AUTOSAR XML (schema 00048)
package /ComponentTypes
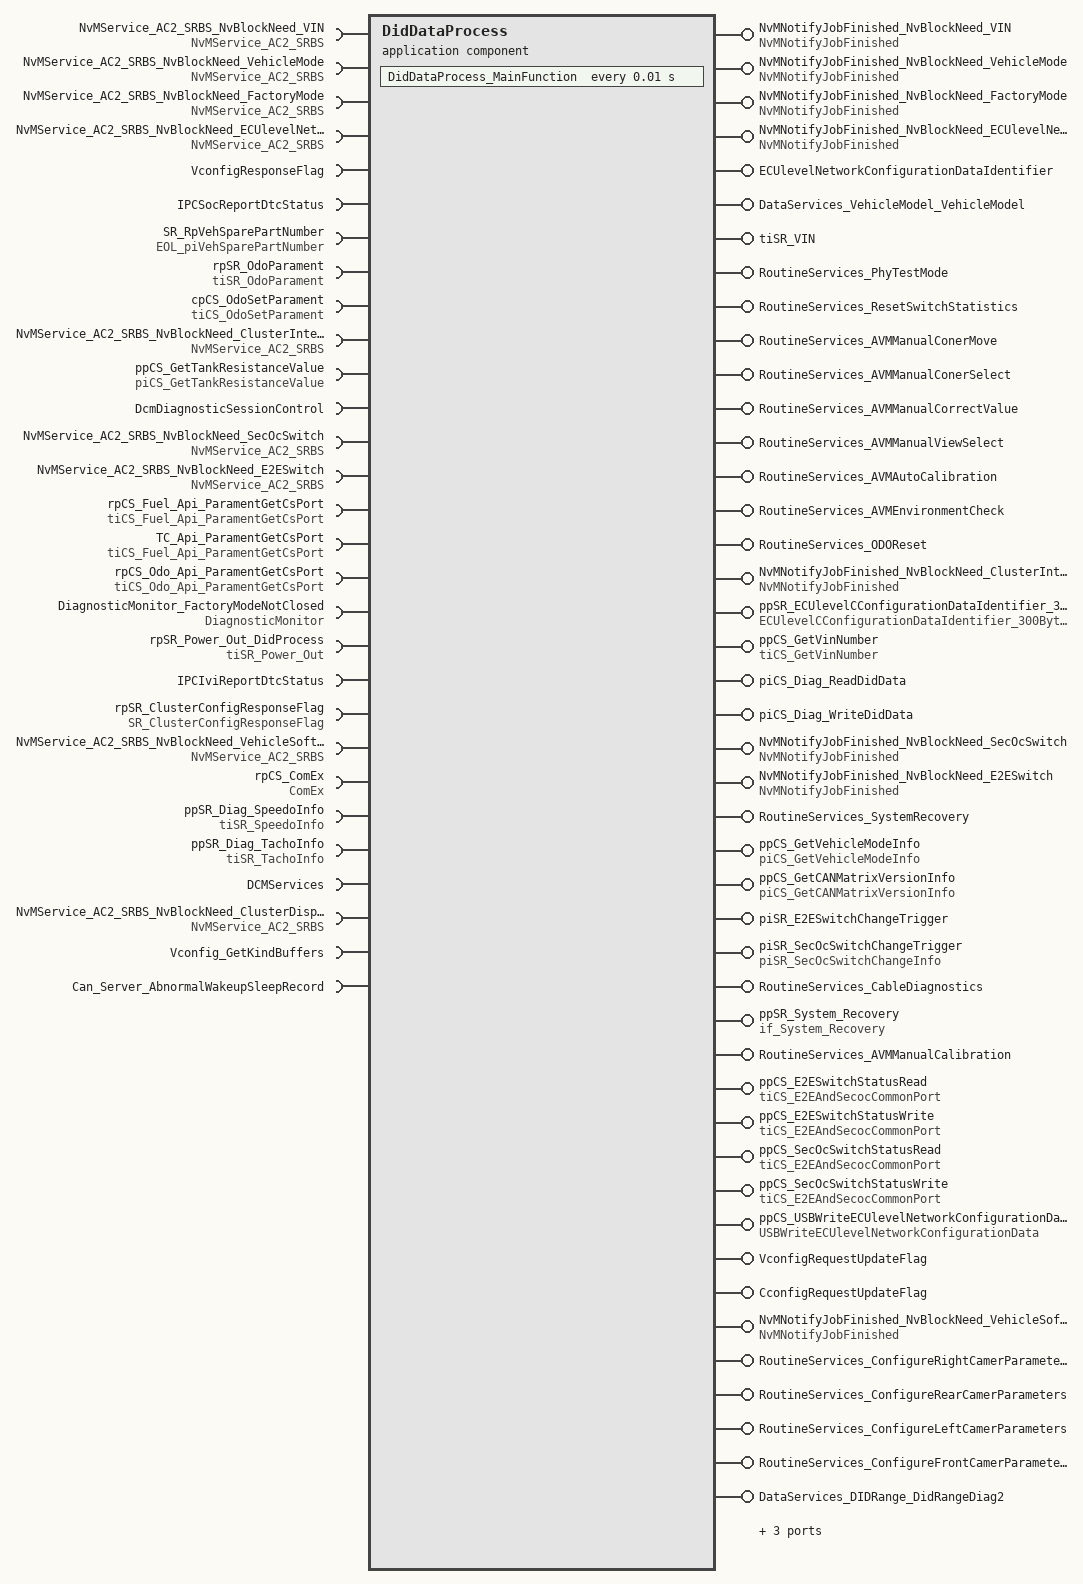
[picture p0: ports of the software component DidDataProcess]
  application sw component type DidDataProcess
    provide port NvMNotifyJobFinished_NvBlockNeed_VIN: server-com-spec{operation=JobFinished, queue-length=1}, provided-interface=NvMNotifyJobFinished
    require port NvMService_AC2_SRBS_NvBlockNeed_VIN: required-com-specs=[GetErrorStatus, ReadBlock, SetRamBlockStatus, WriteBlock], required-interface=NvMService_AC2_SRBS
    provide port NvMNotifyJobFinished_NvBlockNeed_VehicleMode: server-com-spec{operation=JobFinished, queue-length=1}, provided-interface=NvMNotifyJobFinished
    require port NvMService_AC2_SRBS_NvBlockNeed_VehicleMode: required-com-specs=[GetErrorStatus, ReadBlock, SetRamBlockStatus, WriteBlock], required-interface=NvMService_AC2_SRBS
    provide port NvMNotifyJobFinished_NvBlockNeed_FactoryMode: server-com-spec{operation=JobFinished, queue-length=1}, provided-interface=NvMNotifyJobFinished
    require port NvMService_AC2_SRBS_NvBlockNeed_FactoryMode: required-com-specs=[GetErrorStatus, ReadBlock, SetRamBlockStatus, WriteBlock], required-interface=NvMService_AC2_SRBS
    provide port NvMNotifyJobFinished_NvBlockNeed_ECUlevelNetworkConfigurationData: server-com-spec{operation=JobFinished, queue-length=1}, provided-interface=NvMNotifyJobFinished
    require port NvMService_AC2_SRBS_NvBlockNeed_ECUlevelNetworkConfigurationData: required-com-specs=[GetErrorStatus, ReadBlock, SetRamBlockStatus, WriteBlock], required-interface=NvMService_AC2_SRBS
    provide port ECUlevelNetworkConfigurationDataIdentifier: nonqueued-sender-com-spec{data-element=Element, init-value=200 x 0}, provided-interface=ECUlevelNetworkConfigurationDataIdentifier
    require port VconfigResponseFlag: nonqueued-receiver-com-spec{data-element=VconfigResponseFlag, filter=data-filter-type=ALWAYS, init-value=0}, required-interface=VconfigResponseFlag
    require port IPCSocReportDtcStatus: client-com-spec=IpcSocReportDtcStatus, required-interface=IPCSocReportDtcStatus
    11 x provide port:
      DataServices_VehicleModel_VehicleModel: provided-interface=DataServices_VehicleModel_VehicleModel
        provided-com-specs:
          operation=WriteData, queue-length=1
          operation=ConditionCheckRead, queue-length=1
          operation=ReadData, queue-length=1
      tiSR_VIN: nonqueued-sender-com-spec{data-element=Element, init-value=17 x 0}, provided-interface=tiSR_VIN
      RoutineServices_PhyTestMode: server-com-spec{operation=Start, queue-length=1}, provided-interface=RoutineServices_PhyTestMode
      RoutineServices_ResetSwitchStatistics: server-com-spec{operation=Start, queue-length=1}, provided-interface=RoutineServices_ResetSwitchStatistics
      RoutineServices_AVMManualConerMove: provided-com-specs=[{operation=RequestResults, queue-length=1}, {operation=Start, queue-length=1}], provided-interface=RoutineServices_AVMManualConerMove
      RoutineServices_AVMManualConerSelect: provided-com-specs=[{operation=RequestResults, queue-length=1}, {operation=Start, queue-length=1}], provided-interface=RoutineServices_AVMManualConerSelect
      RoutineServices_AVMManualCorrectValue: provided-com-specs=[{operation=RequestResults, queue-length=1}, {operation=Start, queue-length=1}], provided-interface=RoutineServices_AVMManualCorrectValue
      RoutineServices_AVMManualViewSelect: provided-com-specs=[{operation=RequestResults, queue-length=1}, {operation=Start, queue-length=1}], provided-interface=RoutineServices_AVMManualViewSelect
      RoutineServices_AVMAutoCalibration: provided-com-specs=[{operation=RequestResults, queue-length=1}, {operation=Start, queue-length=1}], provided-interface=RoutineServices_AVMAutoCalibration
      RoutineServices_AVMEnvironmentCheck: provided-com-specs=[{operation=RequestResults, queue-length=1}, {operation=Start, queue-length=1}], provided-interface=RoutineServices_AVMEnvironmentCheck
      RoutineServices_ODOReset: provided-com-specs=[{operation=Start, queue-length=1}, {operation=RequestResults, queue-length=1}], provided-interface=RoutineServices_ODOReset
    require port SR_RpVehSparePartNumber: nonqueued-receiver-com-spec{data-element=SparePartNumber, filter=data-filter-type=ALWAYS, init-value=13 x 0}, required-interface=EOL_piVehSparePartNumber
    require port rpSR_OdoParament: nonqueued-receiver-com-spec{data-element=Element, filter=data-filter-type=ALWAYS, init-value=constant-reference=SocRpOdoDataInit}, required-interface=tiSR_OdoParament
    require port cpCS_OdoSetParament: client-com-spec=Operation, required-interface=tiCS_OdoSetParament
    provide port NvMNotifyJobFinished_NvBlockNeed_ClusterInternalConfiguration: server-com-spec{operation=JobFinished, queue-length=1}, provided-interface=NvMNotifyJobFinished
    require port NvMService_AC2_SRBS_NvBlockNeed_ClusterInternalConfiguration: required-com-specs=[WriteBlock, SetRamBlockStatus, ReadBlock, GetErrorStatus], required-interface=NvMService_AC2_SRBS
    require port ppCS_GetTankResistanceValue: client-com-spec=Operation, required-interface=piCS_GetTankResistanceValue
    require port DcmDiagnosticSessionControl: mode-switch-receiver-com-spec=DcmDiagnosticSessionControl, required-interface=DcmDiagnosticSessionControl
    5 x provide port:
      ppSR_ECUlevelCConfigurationDataIdentifier_300Bytes: nonqueued-sender-com-spec=Element, provided-interface=ECUlevelCConfigurationDataIdentifier_300Bytes
      ppCS_GetVinNumber: server-com-spec{operation=Operation, queue-length=1}, provided-interface=tiCS_GetVinNumber
      piCS_Diag_ReadDidData: server-com-spec{operation=Operation, queue-length=1}, provided-interface=piCS_Diag_ReadDidData
      piCS_Diag_WriteDidData: server-com-spec{operation=Operation, queue-length=1}, provided-interface=piCS_Diag_WriteDidData
      NvMNotifyJobFinished_NvBlockNeed_SecOcSwitch: server-com-spec{operation=JobFinished, queue-length=1}, provided-interface=NvMNotifyJobFinished
    require port NvMService_AC2_SRBS_NvBlockNeed_SecOcSwitch: required-com-specs=[WriteBlock, SetRamBlockStatus, ReadBlock, GetErrorStatus], required-interface=NvMService_AC2_SRBS
    provide port NvMNotifyJobFinished_NvBlockNeed_E2ESwitch: server-com-spec{operation=JobFinished, queue-length=1}, provided-interface=NvMNotifyJobFinished
    require port NvMService_AC2_SRBS_NvBlockNeed_E2ESwitch: required-com-specs=[WriteBlock, SetRamBlockStatus, ReadBlock, GetErrorStatus], required-interface=NvMService_AC2_SRBS
    provide port RoutineServices_SystemRecovery: server-com-spec{operation=Start, queue-length=1}, provided-interface=RoutineServices_SystemRecovery
    require port rpCS_Fuel_Api_ParamentGetCsPort: client-com-spec=Operation, required-interface=tiCS_Fuel_Api_ParamentGetCsPort
    require port TC_Api_ParamentGetCsPort: client-com-spec=Operation, required-interface=tiCS_Fuel_Api_ParamentGetCsPort
    provide port ppCS_GetVehicleModeInfo: server-com-spec{operation=Data, queue-length=1}, provided-interface=piCS_GetVehicleModeInfo
    provide port ppCS_GetCANMatrixVersionInfo: server-com-spec{operation=Data, queue-length=1}, provided-interface=piCS_GetCANMatrixVersionInfo
    require port rpCS_Odo_Api_ParamentGetCsPort: client-com-spec=Operation, required-interface=tiCS_Odo_Api_ParamentGetCsPort
    4 x provide port:
      piSR_E2ESwitchChangeTrigger: nonqueued-sender-com-spec{data-element=Element, init-value=0}, provided-interface=piSR_E2ESwitchChangeTrigger
      piSR_SecOcSwitchChangeTrigger: nonqueued-sender-com-spec=Element, provided-interface=piSR_SecOcSwitchChangeInfo
      RoutineServices_CableDiagnostics: server-com-spec{operation=Start, queue-length=1}, provided-interface=RoutineServices_CableDiagnostics
      ppSR_System_Recovery: nonqueued-sender-com-spec{data-element=System_Recovery, init-value=0}, provided-interface=if_System_Recovery
    require port DiagnosticMonitor_FactoryModeNotClosed: required-interface=DiagnosticMonitor
      required-com-specs:
        GetEventExtendedDataRecordEx
        GetEventFreezeFrameDataEx
        GetFaultDetectionCounter
        GetDTCOfEvent
        GetEventTested
        GetEventFailed
        GetEventStatus
        GetEventUdsStatus
        ResetEventDebounceStatus
        ResetEventStatus
        SetEventStatus
    provide port RoutineServices_AVMManualCalibration: provided-interface=RoutineServices_AVMManualCalibration
      provided-com-specs:
        operation=Stop, queue-length=1
        operation=RequestResults, queue-length=1
        operation=Start, queue-length=1
    require port rpSR_Power_Out_DidProcess: nonqueued-receiver-com-spec{data-element=SystemStateOut, filter=data-filter-type=ALWAYS, init-value=fields=[ClusterState:0, IVIState:0, HUDState:0, ConsoleState:0, KL15State:0, {short-label=s_PowerVoltage, fields=[state:0, value:0]}, SP_State:0, {short-label=s_TempVoltage, fields=[state:0, temperature:0]}]}, required-interface=tiSR_Power_Out
    4 x provide port, all with server-com-spec{operation=Operation, queue-length=1}, provided-interface=tiCS_E2EAndSecocCommonPort:
      ppCS_E2ESwitchStatusRead
      ppCS_E2ESwitchStatusWrite
      ppCS_SecOcSwitchStatusRead
      ppCS_SecOcSwitchStatusWrite
    require port IPCIviReportDtcStatus: client-com-spec=IpcIviReportDtcSts, required-interface=IPCIviReportDtcStatus
    require port rpSR_ClusterConfigResponseFlag: nonqueued-receiver-com-spec{data-element=ClusterConfigResponseFlag, filter=data-filter-type=ALWAYS, init-value=0}, required-interface=SR_ClusterConfigResponseFlag
    provide port ppCS_USBWriteECUlevelNetworkConfigurationData: server-com-spec{operation=USBWriteData, queue-length=1}, provided-interface=USBWriteECUlevelNetworkConfigurationData
    provide port VconfigRequestUpdateFlag: nonqueued-sender-com-spec{data-element=VconfigRequestUpdateFlag, init-value=0}, provided-interface=VconfigRequestUpdateFlag
    provide port CconfigRequestUpdateFlag: nonqueued-sender-com-spec{data-element=CconfigRequestUpdateFlag, init-value=0}, provided-interface=CconfigRequestUpdateFlag
    require port NvMService_AC2_SRBS_NvBlockNeed_VehicleSoftwareVersion: required-com-specs=[WriteBlock, SetRamBlockStatus, ReadBlock, GetErrorStatus], required-interface=NvMService_AC2_SRBS
    provide port NvMNotifyJobFinished_NvBlockNeed_VehicleSoftwareVersion: server-com-spec{operation=JobFinished, queue-length=1}, provided-interface=NvMNotifyJobFinished
    require port rpCS_ComEx: required-com-specs=[SendSignal, ReceiveSignal, GetRxE2EStatus], required-interface=ComEx
    4 x provide port, all with provided-com-specs=[{operation=RequestResults, queue-length=1}, {operation=Start, queue-length=1}]:
      RoutineServices_ConfigureRightCamerParameters: provided-interface=RoutineServices_ConfigureRightCamerParameters
      RoutineServices_ConfigureRearCamerParameters: provided-interface=RoutineServices_ConfigureRearCamerParameters
      RoutineServices_ConfigureLeftCamerParameters: provided-interface=RoutineServices_ConfigureLeftCamerParameters
      RoutineServices_ConfigureFrontCamerParameters: provided-interface=RoutineServices_ConfigureFrontCamerParameters
    require port ppSR_Diag_SpeedoInfo: nonqueued-receiver-com-spec{data-element=Element, filter=data-filter-type=ALWAYS, init-value=fields=[OverSpdWrnFlg:0, VehRunSts:0, IndicateSpeed:0, RealSpeed:0, IndicateSpeedMile:0, RealSpeedMile:0, RealSpeedBak:0, Msg_missingSts:0, VehSpdVld:0]}, required-interface=tiSR_SpeedoInfo
    require port ppSR_Diag_TachoInfo: nonqueued-receiver-com-spec{data-element=Element, filter=data-filter-type=ALWAYS, init-value=fields=[EngRunSts:0, EngSpd:0, TimeOutFlag:0, EngSpdBak:0, Msg_missingSts:0]}, required-interface=tiSR_TachoInfo
    require port DCMServices: required-interface=DCMServices
      required-com-specs:
        GetRequestKind
        SetActiveDiagnostic
        GetSecurityLevel
        ResetToDefaultSession
        GetSesCtrlType
        GetActiveProtocol
    provide port DataServices_DIDRange_DidRangeDiag2: provided-interface=DataServices_DIDRange_DidRangeDiag2
      provided-com-specs:
        operation=IsDidAvailable, queue-length=1
        operation=WriteDidData, queue-length=1
        operation=ReadDidData, queue-length=1
    provide port DataServices_DIDRange_DidRangeDiag1: provided-interface=DataServices_DIDRange_DidRangeDiag1
      provided-com-specs:
        operation=IsDidAvailable, queue-length=1
        operation=WriteDidData, queue-length=1
        operation=ReadDidData, queue-length=1
    provide port NvMNotifyJobFinished_NvBlockNeed_ClusterDisplayHMIAdjustmentOffset: server-com-spec{operation=JobFinished, queue-length=1}, provided-interface=NvMNotifyJobFinished
    require port NvMService_AC2_SRBS_NvBlockNeed_ClusterDisplayHMIAdjustmentOffset: required-com-specs=[WriteBlock, SetRamBlockStatus, ReadBlock, GetErrorStatus], required-interface=NvMService_AC2_SRBS
    require port Vconfig_GetKindBuffers: nonqueued-receiver-com-spec{data-element=AllKinds, filter=data-filter-type=ALWAYS, init-value=600 x 0}, required-interface=Vconfig_GetKindBuffers
    provide port RoutineServices_RequestCertificateStatus: provided-com-specs=[{operation=RequestResults, queue-length=1}, {operation=Start, queue-length=1}], provided-interface=RoutineServices_RequestCertificateStatus
    require port Can_Server_AbnormalWakeupSleepRecord: client-com-spec=Get, required-interface=Can_Server_AbnormalWakeupSleepRecord
    behavior DidDataProcess_InternalBehavior
      ar-typed-per-instance-memorys:
        10 x data, all with sw-calibration-access=READ-ONLY:
          NvBlockNeed_VIN_MirrorBlock: type=A_17Bytes
          NvBlockNeed_VehicleMode_MirrorBlock: type=Dcm_Data20ByteType
          NvBlockNeed_FactoryMode_MirrorBlock: type=A_1Bytes
          NvBlockNeed_ECUlevelNetworkConfigurationData_MirrorBlock: type=A_200Bytes
          NvBlockNeed_HUTInternalConfiguration_MirrorBlock: type=Dcm_Data4ByteType
          NvBlockNeed_ClusterInternalConfiguration_MirrorBlock: type=A_300Bytes
          NvBlockNeed_SecOcSwitch_MirrorBlock: type=A_1Bytes
          NvBlockNeed_E2ESwitch_MirrorBlock: type=A_1Bytes
          NvBlockNeed_VehicleSoftwareVersion_MirrorBlock: type=A_30Bytes
          NvBlockNeed_ClusterDisplayHMIAdjustmentOffset_MirrorBlock: type=A_8Bytes
      init event DidDataProcess_InitEvent: start-on-event=DidDataProcess_Init
      timing event TMT_DidDataProcess_MainFunction: start-on-event=DidDataProcess_MainFunction, period=0.01
      59 x operation invoked event:
        OIT_NvMNotifyJobFinished_NvBlockNeed_VIN_JobFinished_NvMNotifyJobFinished_NvBlockNeed_VIN_JobFinished: start-on-event=NvMNotifyJobFinished_NvBlockNeed_VIN_JobFinished, operation=NvMNotifyJobFinished_NvBlockNeed_VIN.JobFinished
        OIT_NvMNotifyJobFinished_NvBlockNeed_VehicleMode_JobFinished_NvMNotifyJobFinished_NvBlockNeed_VehicleMode_JobFinished: start-on-event=NvMNotifyJobFinished_NvBlockNeed_VehicleMode_JobFinished, operation=NvMNotifyJobFinished_NvBlockNeed_VehicleMode.JobFinished
        OIT_NvMNotifyJobFinished_NvBlockNeed_FactoryMode_JobFinished_NvMNotifyJobFinished_NvBlockNeed_FactoryMode_JobFinished: start-on-event=NvMNotifyJobFinished_NvBlockNeed_FactoryMode_JobFinished, operation=NvMNotifyJobFinished_NvBlockNeed_FactoryMode.JobFinished
        OIT_NvMNotifyJobFinished_NvBlockNeed_ECUlevelNetworkConfigurationData_JobFinished_NvMNotifyJobFinished_NvBlockNeed_ECUleB6E309F8: start-on-event=NvMNotifyJobFinished_NvBlockNeed_ECUlevelNetworkConfigurationData_JobFinished, operation=NvMNotifyJobFinished_NvBlockNeed_ECUlevelNetworkConfigurationData.JobFinished
        OIT_DataServices_VehicleModel_VehicleModel_WriteData_DataServices_VehicleModel_VehicleModel_WriteData: start-on-event=DataServices_VehicleModel_VehicleModel_WriteData, operation=DataServices_VehicleModel_VehicleModel.WriteData
        OIT_DataServices_VehicleModel_VehicleModel_ConditionCheckRead_DataServices_VehicleModel_VehicleModel_ConditionCheckRead: start-on-event=DataServices_VehicleModel_VehicleModel_ConditionCheckRead, operation=DataServices_VehicleModel_VehicleModel.ConditionCheckRead
        OIT_DataServices_VehicleModel_VehicleModel_ReadData_DataServices_VehicleModel_VehicleModel_ReadData: start-on-event=DataServices_VehicleModel_VehicleModel_ReadData, operation=DataServices_VehicleModel_VehicleModel.ReadData
        OIT_RoutineServices_ResetSwitchStatistics_Start_RoutineServices_ResetSwitchStatistics_Start: start-on-event=RoutineServices_ResetSwitchStatistics_Start, operation=RoutineServices_ResetSwitchStatistics.Start
        OIT_RoutineServices_PhyTestMode_Start_RoutineServices_PhyTestMode_Start: start-on-event=RoutineServices_PhyTestMode_Start, operation=RoutineServices_PhyTestMode.Start
        OIT_RoutineServices_AVMEnvironmentCheck_RequestResults_RoutineServices_AVMEnvironmentCheck_RequestResults: start-on-event=RoutineServices_AVMEnvironmentCheck_RequestResults, operation=RoutineServices_AVMEnvironmentCheck.RequestResults
        OIT_RoutineServices_AVMEnvironmentCheck_Start_RoutineServices_AVMEnvironmentCheck_Start: start-on-event=RoutineServices_AVMEnvironmentCheck_Start, operation=RoutineServices_AVMEnvironmentCheck.Start
        OIT_RoutineServices_AVMManualConerMove_RequestResults_RoutineServices_AVMManualConerMove_RequestResults: start-on-event=RoutineServices_AVMManualConerMove_RequestResults, operation=RoutineServices_AVMManualConerMove.RequestResults
        OIT_RoutineServices_AVMManualConerMove_Start_RoutineServices_AVMManualConerMove_Start: start-on-event=RoutineServices_AVMManualConerMove_Start, operation=RoutineServices_AVMManualConerMove.Start
        OIT_RoutineServices_AVMManualConerSelect_RequestResults_RoutineServices_AVMManualConerSelect_RequestResults: start-on-event=RoutineServices_AVMManualConerSelect_RequestResults, operation=RoutineServices_AVMManualConerSelect.RequestResults
        OIT_RoutineServices_AVMManualConerSelect_Start_RoutineServices_AVMManualConerSelect_Start: start-on-event=RoutineServices_AVMManualConerSelect_Start, operation=RoutineServices_AVMManualConerSelect.Start
        OIT_RoutineServices_AVMManualCorrectValue_RequestResults_RoutineServices_AVMManualCorrectValue_RequestResults: start-on-event=RoutineServices_AVMManualCorrectValue_RequestResults, operation=RoutineServices_AVMManualCorrectValue.RequestResults
        OIT_RoutineServices_AVMManualCorrectValue_Start_RoutineServices_AVMManualCorrectValue_Start: start-on-event=RoutineServices_AVMManualCorrectValue_Start, operation=RoutineServices_AVMManualCorrectValue.Start
        OIT_RoutineServices_AVMManualViewSelect_RequestResults_RoutineServices_AVMManualViewSelect_RequestResults: start-on-event=RoutineServices_AVMManualViewSelect_RequestResults, operation=RoutineServices_AVMManualViewSelect.RequestResults
        OIT_RoutineServices_AVMManualViewSelect_Start_RoutineServices_AVMManualViewSelect_Start: start-on-event=RoutineServices_AVMManualViewSelect_Start, operation=RoutineServices_AVMManualViewSelect.Start
        OIT_RoutineServices_AVMAutoCalibration_RequestResults_RoutineServices_AVMAutoCalibration_RequestResults: start-on-event=RoutineServices_AVMAutoCalibration_RequestResults, operation=RoutineServices_AVMAutoCalibration.RequestResults
        OIT_RoutineServices_AVMAutoCalibration_Start_RoutineServices_AVMAutoCalibration_Start: start-on-event=RoutineServices_AVMAutoCalibration_Start, operation=RoutineServices_AVMAutoCalibration.Start
        OIT_NvMNotifyJobFinished_NvBlockNeed_ClusterInternalConfiguration_JobFinished_NvMNotifyJobFinished_NvBlockNeed_ClusterIn67862731: start-on-event=NvMNotifyJobFinished_NvBlockNeed_ClusterInternalConfiguration_JobFinished, operation=NvMNotifyJobFinished_NvBlockNeed_ClusterInternalConfiguration.JobFinished
        OIT_AppGetVinNumberFunction_ppCS_GetVinNumber_Operation: start-on-event=AppGetVinNumberFunction, operation=ppCS_GetVinNumber.Operation
        OIT_piCS_Diag_WriteDidData_Operation_piCS_Diag_WriteDidData_Operation: start-on-event=ppCS_Diag_WriteDidData_Operation, operation=piCS_Diag_WriteDidData.Operation
        OIT_piCS_Diag_ReadDidData_Operation_piCS_Diag_ReadDidData_Operation: start-on-event=ppCS_Diag_ReadDidData_Operation, operation=piCS_Diag_ReadDidData.Operation
        OIT_NvMNotifyJobFinished_NvBlockNeed_E2ESwitch_JobFinished_NvMNotifyJobFinished_NvBlockNeed_E2ESwitch_JobFinished: start-on-event=NvMNotifyJobFinished_NvBlockNeed_E2ESwitch_JobFinished, operation=NvMNotifyJobFinished_NvBlockNeed_E2ESwitch.JobFinished
        OIT_NvMNotifyJobFinished_NvBlockNeed_SecOcSwitch_JobFinished_NvMNotifyJobFinished_NvBlockNeed_SecOcSwitch_JobFinished: start-on-event=NvMNotifyJobFinished_NvBlockNeed_SecOcSwitch_JobFinished, operation=NvMNotifyJobFinished_NvBlockNeed_SecOcSwitch.JobFinished
        OIT_RoutineServices_SystemRecovery_Start_RoutineServices_SystemRecovery_Start: start-on-event=RoutineServices_SystemRecovery_Start, operation=RoutineServices_SystemRecovery.Start
        OIT_ppCS_GetCANMatrixVersionInfo_Data_ppCS_GetCANMatrixVersionInfo_Data: start-on-event=GetCANMatrixVersionInfo_Data, operation=ppCS_GetCANMatrixVersionInfo.Data
        OIT_ppCS_GetVehicleModeInfo_Data_ppCS_GetVehicleModeInfo_Data: start-on-event=GetVehicleModeInfo_Data, operation=ppCS_GetVehicleModeInfo.Data
        OIT_RoutineServices_ODOReset_RequestResults_RoutineServices_ODOReset_RequestResults: start-on-event=RoutineServices_ODOReset_RequestResults, operation=RoutineServices_ODOReset.RequestResults
        OIT_RoutineServices_ODOReset_Start_RoutineServices_ODOReset_Start: start-on-event=RoutineServices_ODOReset_Start, operation=RoutineServices_ODOReset.Start
        OIT_RoutineServices_CableDiagnostics_Start_RoutineServices_CableDiagnostics_Start: start-on-event=RoutineServices_CableDiagnostics_Start, operation=RoutineServices_CableDiagnostics.Start
        OIT_RoutineServices_AVMManualCalibration_Stop_RoutineServices_AVMManualCalibration_Stop: start-on-event=RoutineServices_AVMManualCalibration_Stop, operation=RoutineServices_AVMManualCalibration.Stop
        OIT_RoutineServices_AVMManualCalibration_RequestResults_RoutineServices_AVMManualCalibration_RequestResults: start-on-event=RoutineServices_AVMManualCalibration_RequestResults, operation=RoutineServices_AVMManualCalibration.RequestResults
        OIT_RoutineServices_AVMManualCalibration_Start_RoutineServices_AVMManualCalibration_Start: start-on-event=RoutineServices_AVMManualCalibration_Start, operation=RoutineServices_AVMManualCalibration.Start
        OIT_ppCS_SecOcSwitchStatusRead_Operation_ppCS_SecOcSwitchStatusRead_Operation: start-on-event=SecOcSwitchStatusRead, operation=ppCS_SecOcSwitchStatusRead.Operation
        OIT_ppCS_SecOcSwitchStatusWrite_Operation_ppCS_SecOcSwitchStatusWrite_Operation: start-on-event=SecOcSwitchStatusWrite, operation=ppCS_SecOcSwitchStatusWrite.Operation
        OIT_ppCS_E2ESwitchStatusRead_Operation_ppCS_E2ESwitchStatusRead_Operation: start-on-event=E2ESwitchStatusRead, operation=ppCS_E2ESwitchStatusRead.Operation
        OIT_ppCS_E2ESwitchStatusWrite_Operation_ppCS_E2ESwitchStatusWrite_Operation: start-on-event=E2ESwitchStatusWrite, operation=ppCS_E2ESwitchStatusWrite.Operation
        OIT_ppCS_USBWriteECUlevelNetworkConfigurationData_USBWriteData_ppCS_USBWriteECUlevelNetworkConfigurationData_USBWriteData: start-on-event=ppCS_USBWriteECUlevelNetworkConfigurationData_USBWriteData, operation=ppCS_USBWriteECUlevelNetworkConfigurationData.USBWriteData
        OIT_NvMNotifyJobFinished_NvBlockNeed_VehicleSoftwareVersion_JobFinished_NvMNotifyJobFinished_NvBlockNeed_VehicleSoftware10887BBF: start-on-event=NvMNotifyJobFinished_NvBlockNeed_VehicleSoftwareVersion_JobFinished, operation=NvMNotifyJobFinished_NvBlockNeed_VehicleSoftwareVersion.JobFinished
        OIT_RoutineServices_ConfigureRightCamerParameters_RequestResults_RoutineServices_ConfigureRightCamerParameters_RequestResults: start-on-event=RoutineServices_ConfigureRightCamerParameters_RequestResults, operation=RoutineServices_ConfigureRightCamerParameters.RequestResults
        OIT_RoutineServices_ConfigureRightCamerParameters_Start_RoutineServices_ConfigureRightCamerParameters_Start: start-on-event=RoutineServices_ConfigureRightCamerParameters_Start, operation=RoutineServices_ConfigureRightCamerParameters.Start
        OIT_RoutineServices_ConfigureRearCamerParameters_RequestResults_RoutineServices_ConfigureRearCamerParameters_RequestResults: start-on-event=RoutineServices_ConfigureRearCamerParameters_RequestResults, operation=RoutineServices_ConfigureRearCamerParameters.RequestResults
        OIT_RoutineServices_ConfigureRearCamerParameters_Start_RoutineServices_ConfigureRearCamerParameters_Start: start-on-event=RoutineServices_ConfigureRearCamerParameters_Start, operation=RoutineServices_ConfigureRearCamerParameters.Start
        OIT_RoutineServices_ConfigureLeftCamerParameters_RequestResults_RoutineServices_ConfigureLeftCamerParameters_RequestResults: start-on-event=RoutineServices_ConfigureLeftCamerParameters_RequestResults, operation=RoutineServices_ConfigureLeftCamerParameters.RequestResults
        OIT_RoutineServices_ConfigureLeftCamerParameters_Start_RoutineServices_ConfigureLeftCamerParameters_Start: start-on-event=RoutineServices_ConfigureLeftCamerParameters_Start, operation=RoutineServices_ConfigureLeftCamerParameters.Start
        OIT_RoutineServices_ConfigureFrontCamerParameters_RequestResults_RoutineServices_ConfigureFrontCamerParameters_RequestResults: start-on-event=RoutineServices_ConfigureFrontCamerParameters_RequestResults, operation=RoutineServices_ConfigureFrontCamerParameters.RequestResults
        OIT_RoutineServices_ConfigureFrontCamerParameters_Start_RoutineServices_ConfigureFrontCamerParameters_Start: start-on-event=RoutineServices_ConfigureFrontCamerParameters_Start, operation=RoutineServices_ConfigureFrontCamerParameters.Start
        OIT_DataServices_DIDRange_DidRangeDiag2_IsDidAvailable_DataServices_DIDRange_DidRangeDiag2_IsDidAvailable: start-on-event=DataServices_DIDRange_DidRangeDiag2_IsDidAvailable, operation=DataServices_DIDRange_DidRangeDiag2.IsDidAvailable
        OIT_DataServices_DIDRange_DidRangeDiag2_WriteDidData_DataServices_DIDRange_DidRangeDiag2_WriteDidData: start-on-event=DataServices_DIDRange_DidRangeDiag2_WriteDidData, operation=DataServices_DIDRange_DidRangeDiag2.WriteDidData
        OIT_DataServices_DIDRange_DidRangeDiag2_ReadDidData_DataServices_DIDRange_DidRangeDiag2_ReadDidData: start-on-event=DataServices_DIDRange_DidRangeDiag2_ReadDidData, operation=DataServices_DIDRange_DidRangeDiag2.ReadDidData
        OIT_DataServices_DIDRange_DidRangeDiag1_IsDidAvailable_DataServices_DIDRange_DidRangeDiag1_IsDidAvailable: start-on-event=DataServices_DIDRange_DidRangeDiag1_IsDidAvailable, operation=DataServices_DIDRange_DidRangeDiag1.IsDidAvailable
        OIT_DataServices_DIDRange_DidRangeDiag1_WriteDidData_DataServices_DIDRange_DidRangeDiag1_WriteDidData: start-on-event=DataServices_DIDRange_DidRangeDiag1_WriteDidData, operation=DataServices_DIDRange_DidRangeDiag1.WriteDidData
        OIT_DataServices_DIDRange_DidRangeDiag1_ReadDidData_DataServices_DIDRange_DidRangeDiag1_ReadDidData: start-on-event=DataServices_DIDRange_DidRangeDiag1_ReadDidData, operation=DataServices_DIDRange_DidRangeDiag1.ReadDidData
        OIT_NvMNotifyJobFinished_NvBlockNeed_ClusterDisplayHMIAdjustmentOffset_JobFinished_NvMNotifyJobFinished_NvBlockNeed_Clus23676530: start-on-event=NvMNotifyJobFinished_NvBlockNeed_ClusterDisplayHMIAdjustmentOffset_JobFinished, operation=NvMNotifyJobFinished_NvBlockNeed_ClusterDisplayHMIAdjustmentOffset.JobFinished
        OIT_RoutineServices_RequestCertificateStatus_RequestResults_RoutineServices_RequestCertificateStatus_RequestResults: start-on-event=RoutineServices_RequestCertificateStatus_RequestResults, operation=RoutineServices_RequestCertificateStatus.RequestResults
        OIT_RoutineServices_RequestCertificateStatus_Start_RoutineServices_RequestCertificateStatus_Start: start-on-event=RoutineServices_RequestCertificateStatus_Start, operation=RoutineServices_RequestCertificateStatus.Start
      port-api-options:
        enable-take-address=false, error-handling=NO-TRANSFORMER-ERROR-HANDLING, indirect-api=false, port=cpCS_OdoSetParament
        enable-take-address=true, error-handling=NO-TRANSFORMER-ERROR-HANDLING, indirect-api=false, port=piCS_Diag_WriteDidData
        enable-take-address=true, error-handling=NO-TRANSFORMER-ERROR-HANDLING, indirect-api=false, port=piCS_Diag_ReadDidData
        enable-take-address=true, error-handling=NO-TRANSFORMER-ERROR-HANDLING, indirect-api=false, port=ppCS_GetVehicleModeInfo
        enable-take-address=true, error-handling=NO-TRANSFORMER-ERROR-HANDLING, indirect-api=false, port=ppCS_GetCANMatrixVersionInfo
      61 x runnable:
        DidDataProcess_Init
        DidDataProcess_MainFunction: mode-access-point=DcmDiagnosticSessionControl.DcmDiagnosticSessionControl
          data-receive-point-by-arguments:
            8 x access:
              REC_SR_RpVehSparePartNumber_SparePartNumber: accessed-variable=SR_RpVehSparePartNumber.SparePartNumber
              REC_ppSR_Diag_SpeedoInfo_Element: accessed-variable=ppSR_Diag_SpeedoInfo.Element
              REC_ppSR_Diag_TachoInfo_Element: accessed-variable=ppSR_Diag_TachoInfo.Element
              REC_VconfigResponseFlag_VconfigResponseFlag: accessed-variable=VconfigResponseFlag.VconfigResponseFlag
              REC_rpSR_ClusterConfigResponseFlag_ClusterConfigResponseFlag: accessed-variable=rpSR_ClusterConfigResponseFlag.ClusterConfigResponseFlag
              REC_rpSR_OdoParament_Element: accessed-variable=rpSR_OdoParament.Element
              REC_rpSR_Power_Out_DidProcess_SystemStateOut: accessed-variable=rpSR_Power_Out_DidProcess.SystemStateOut
              REC_Vconfig_GetKindBuffers_Kind600Bytes: accessed-variable=Vconfig_GetKindBuffers.AllKinds
          data-send-points:
            8 x access:
              SEND_tiSR_VIN_Element: accessed-variable=tiSR_VIN.Element
              SEND_CconfigRequestUpdateFlag_CconfigRequestUpdateFlag: accessed-variable=CconfigRequestUpdateFlag.CconfigRequestUpdateFlag
              SEND_ECUlevelNetworkConfigurationDataIdentifier_Element: accessed-variable=ECUlevelNetworkConfigurationDataIdentifier.Element
              SEND_VconfigRequestUpdateFlag_VconfigRequestUpdateFlag: accessed-variable=VconfigRequestUpdateFlag.VconfigRequestUpdateFlag
              SEND_piSR_E2ESwitchChangeTrigger_Element: accessed-variable=piSR_E2ESwitchChangeTrigger.Element
              SEND_piSR_SecOcSwitchChangeTrigger_Element: accessed-variable=piSR_SecOcSwitchChangeTrigger.Element
              SEND_ppSR_ECUlevelCConfigurationDataIdentifier_300Bytes_Element: accessed-variable=ppSR_ECUlevelCConfigurationDataIdentifier_300Bytes.Element
              SEND_ppSR_System_Recovery_System_Recovery: accessed-variable=ppSR_System_Recovery.System_Recovery
          59 x sync call:
            SC_IPCSocReportDtcStatus_IpcSocReportDtcStatus: operation=IPCSocReportDtcStatus.IpcSocReportDtcStatus
            SC_DiagnosticMonitor_FactoryModeNotClosed_SetEventStatus: operation=DiagnosticMonitor_FactoryModeNotClosed.SetEventStatus
            SC_IPCIviReportDtcStatus_IpcIviReportDtcSts: operation=IPCIviReportDtcStatus.IpcIviReportDtcSts
            SC_rpCS_ComEx_GetRxE2EStatus: operation=rpCS_ComEx.GetRxE2EStatus
            SC_rpCS_ComEx_ReceiveSignal: operation=rpCS_ComEx.ReceiveSignal
            SC_rpCS_ComEx_SendSignal: operation=rpCS_ComEx.SendSignal
            SC_DCMServices_GetActiveProtocol: operation=DCMServices.GetActiveProtocol
            SC_DCMServices_GetRequestKind: operation=DCMServices.GetRequestKind
            SC_DCMServices_GetSecurityLevel: operation=DCMServices.GetSecurityLevel
            SC_DCMServices_GetSesCtrlType: operation=DCMServices.GetSesCtrlType
            SC_DCMServices_ResetToDefaultSession: operation=DCMServices.ResetToDefaultSession
            SC_DCMServices_SetActiveDiagnostic: operation=DCMServices.SetActiveDiagnostic
            SC_DiagnosticMonitor_FactoryModeNotClosed_GetDTCOfEvent: operation=DiagnosticMonitor_FactoryModeNotClosed.GetDTCOfEvent
            SC_DiagnosticMonitor_FactoryModeNotClosed_GetEventExtendedDataRecordEx: operation=DiagnosticMonitor_FactoryModeNotClosed.GetEventExtendedDataRecordEx
            SC_DiagnosticMonitor_FactoryModeNotClosed_GetEventFailed: operation=DiagnosticMonitor_FactoryModeNotClosed.GetEventFailed
            SC_DiagnosticMonitor_FactoryModeNotClosed_GetEventFreezeFrameDataEx: operation=DiagnosticMonitor_FactoryModeNotClosed.GetEventFreezeFrameDataEx
            SC_DiagnosticMonitor_FactoryModeNotClosed_GetEventStatus: operation=DiagnosticMonitor_FactoryModeNotClosed.GetEventStatus
            SC_DiagnosticMonitor_FactoryModeNotClosed_GetEventTested: operation=DiagnosticMonitor_FactoryModeNotClosed.GetEventTested
            SC_DiagnosticMonitor_FactoryModeNotClosed_GetEventUdsStatus: operation=DiagnosticMonitor_FactoryModeNotClosed.GetEventUdsStatus
            SC_DiagnosticMonitor_FactoryModeNotClosed_GetFaultDetectionCounter: operation=DiagnosticMonitor_FactoryModeNotClosed.GetFaultDetectionCounter
            SC_DiagnosticMonitor_FactoryModeNotClosed_ResetEventDebounceStatus: operation=DiagnosticMonitor_FactoryModeNotClosed.ResetEventDebounceStatus
            SC_DiagnosticMonitor_FactoryModeNotClosed_ResetEventStatus: operation=DiagnosticMonitor_FactoryModeNotClosed.ResetEventStatus
            SC_NvMService_AC2_SRBS_NvBlockNeed_ClusterInternalConfiguration_GetErrorStatus: operation=NvMService_AC2_SRBS_NvBlockNeed_ClusterInternalConfiguration.GetErrorStatus
            SC_NvMService_AC2_SRBS_NvBlockNeed_ClusterInternalConfiguration_ReadBlock: operation=NvMService_AC2_SRBS_NvBlockNeed_ClusterInternalConfiguration.ReadBlock
            SC_NvMService_AC2_SRBS_NvBlockNeed_ClusterInternalConfiguration_SetRamBlockStatus: operation=NvMService_AC2_SRBS_NvBlockNeed_ClusterInternalConfiguration.SetRamBlockStatus
            SC_NvMService_AC2_SRBS_NvBlockNeed_ClusterInternalConfiguration_WriteBlock: operation=NvMService_AC2_SRBS_NvBlockNeed_ClusterInternalConfiguration.WriteBlock
            SC_NvMService_AC2_SRBS_NvBlockNeed_E2ESwitch_GetErrorStatus: operation=NvMService_AC2_SRBS_NvBlockNeed_E2ESwitch.GetErrorStatus
            SC_NvMService_AC2_SRBS_NvBlockNeed_E2ESwitch_ReadBlock: operation=NvMService_AC2_SRBS_NvBlockNeed_E2ESwitch.ReadBlock
            SC_NvMService_AC2_SRBS_NvBlockNeed_E2ESwitch_SetRamBlockStatus: operation=NvMService_AC2_SRBS_NvBlockNeed_E2ESwitch.SetRamBlockStatus
            SC_NvMService_AC2_SRBS_NvBlockNeed_E2ESwitch_WriteBlock: operation=NvMService_AC2_SRBS_NvBlockNeed_E2ESwitch.WriteBlock
            SC_NvMService_AC2_SRBS_NvBlockNeed_ECUlevelNetworkConfigurationData_GetErrorStatus: operation=NvMService_AC2_SRBS_NvBlockNeed_ECUlevelNetworkConfigurationData.GetErrorStatus
            SC_NvMService_AC2_SRBS_NvBlockNeed_ECUlevelNetworkConfigurationData_ReadBlock: operation=NvMService_AC2_SRBS_NvBlockNeed_ECUlevelNetworkConfigurationData.ReadBlock
            SC_NvMService_AC2_SRBS_NvBlockNeed_ECUlevelNetworkConfigurationData_SetRamBlockStatus: operation=NvMService_AC2_SRBS_NvBlockNeed_ECUlevelNetworkConfigurationData.SetRamBlockStatus
            SC_NvMService_AC2_SRBS_NvBlockNeed_ECUlevelNetworkConfigurationData_WriteBlock: operation=NvMService_AC2_SRBS_NvBlockNeed_ECUlevelNetworkConfigurationData.WriteBlock
            SC_NvMService_AC2_SRBS_NvBlockNeed_FactoryMode_GetErrorStatus: operation=NvMService_AC2_SRBS_NvBlockNeed_FactoryMode.GetErrorStatus
            SC_NvMService_AC2_SRBS_NvBlockNeed_FactoryMode_ReadBlock: operation=NvMService_AC2_SRBS_NvBlockNeed_FactoryMode.ReadBlock
            SC_NvMService_AC2_SRBS_NvBlockNeed_FactoryMode_SetRamBlockStatus: operation=NvMService_AC2_SRBS_NvBlockNeed_FactoryMode.SetRamBlockStatus
            SC_NvMService_AC2_SRBS_NvBlockNeed_FactoryMode_WriteBlock: operation=NvMService_AC2_SRBS_NvBlockNeed_FactoryMode.WriteBlock
            SC_NvMService_AC2_SRBS_NvBlockNeed_SecOcSwitch_GetErrorStatus: operation=NvMService_AC2_SRBS_NvBlockNeed_SecOcSwitch.GetErrorStatus
            SC_NvMService_AC2_SRBS_NvBlockNeed_SecOcSwitch_ReadBlock: operation=NvMService_AC2_SRBS_NvBlockNeed_SecOcSwitch.ReadBlock
            SC_NvMService_AC2_SRBS_NvBlockNeed_SecOcSwitch_SetRamBlockStatus: operation=NvMService_AC2_SRBS_NvBlockNeed_SecOcSwitch.SetRamBlockStatus
            SC_NvMService_AC2_SRBS_NvBlockNeed_SecOcSwitch_WriteBlock: operation=NvMService_AC2_SRBS_NvBlockNeed_SecOcSwitch.WriteBlock
            SC_NvMService_AC2_SRBS_NvBlockNeed_VIN_GetErrorStatus: operation=NvMService_AC2_SRBS_NvBlockNeed_VIN.GetErrorStatus
            SC_NvMService_AC2_SRBS_NvBlockNeed_VIN_ReadBlock: operation=NvMService_AC2_SRBS_NvBlockNeed_VIN.ReadBlock
            SC_NvMService_AC2_SRBS_NvBlockNeed_VIN_SetRamBlockStatus: operation=NvMService_AC2_SRBS_NvBlockNeed_VIN.SetRamBlockStatus
            SC_NvMService_AC2_SRBS_NvBlockNeed_VIN_WriteBlock: operation=NvMService_AC2_SRBS_NvBlockNeed_VIN.WriteBlock
            SC_NvMService_AC2_SRBS_NvBlockNeed_VehicleMode_GetErrorStatus: operation=NvMService_AC2_SRBS_NvBlockNeed_VehicleMode.GetErrorStatus
            SC_NvMService_AC2_SRBS_NvBlockNeed_VehicleMode_ReadBlock: operation=NvMService_AC2_SRBS_NvBlockNeed_VehicleMode.ReadBlock
            SC_NvMService_AC2_SRBS_NvBlockNeed_VehicleMode_SetRamBlockStatus: operation=NvMService_AC2_SRBS_NvBlockNeed_VehicleMode.SetRamBlockStatus
            SC_NvMService_AC2_SRBS_NvBlockNeed_VehicleMode_WriteBlock: operation=NvMService_AC2_SRBS_NvBlockNeed_VehicleMode.WriteBlock
            SC_NvMService_AC2_SRBS_NvBlockNeed_VehicleSoftwareVersion_GetErrorStatus: operation=NvMService_AC2_SRBS_NvBlockNeed_VehicleSoftwareVersion.GetErrorStatus
            SC_NvMService_AC2_SRBS_NvBlockNeed_VehicleSoftwareVersion_ReadBlock: operation=NvMService_AC2_SRBS_NvBlockNeed_VehicleSoftwareVersion.ReadBlock
            SC_NvMService_AC2_SRBS_NvBlockNeed_VehicleSoftwareVersion_SetRamBlockStatus: operation=NvMService_AC2_SRBS_NvBlockNeed_VehicleSoftwareVersion.SetRamBlockStatus
            SC_NvMService_AC2_SRBS_NvBlockNeed_VehicleSoftwareVersion_WriteBlock: operation=NvMService_AC2_SRBS_NvBlockNeed_VehicleSoftwareVersion.WriteBlock
            SC_NvMService_AC2_SRBS_NvBlockNeed_ClusterDisplayHMIAdjustmentOffset_GetErrorStatus: operation=NvMService_AC2_SRBS_NvBlockNeed_ClusterDisplayHMIAdjustmentOffset.GetErrorStatus
            SC_NvMService_AC2_SRBS_NvBlockNeed_ClusterDisplayHMIAdjustmentOffset_ReadBlock: operation=NvMService_AC2_SRBS_NvBlockNeed_ClusterDisplayHMIAdjustmentOffset.ReadBlock
            SC_NvMService_AC2_SRBS_NvBlockNeed_ClusterDisplayHMIAdjustmentOffset_SetRamBlockStatus: operation=NvMService_AC2_SRBS_NvBlockNeed_ClusterDisplayHMIAdjustmentOffset.SetRamBlockStatus
            SC_NvMService_AC2_SRBS_NvBlockNeed_ClusterDisplayHMIAdjustmentOffset_WriteBlock: operation=NvMService_AC2_SRBS_NvBlockNeed_ClusterDisplayHMIAdjustmentOffset.WriteBlock
            SC_Can_Server_AbnormalWakeupSleepRecord_Get: operation=Can_Server_AbnormalWakeupSleepRecord.Get
        NvMNotifyJobFinished_NvBlockNeed_VIN_JobFinished
        NvMNotifyJobFinished_NvBlockNeed_VehicleMode_JobFinished
        NvMNotifyJobFinished_NvBlockNeed_FactoryMode_JobFinished
        NvMNotifyJobFinished_NvBlockNeed_ECUlevelNetworkConfigurationData_JobFinished
        DataServices_VehicleModel_VehicleModel_WriteData
        DataServices_VehicleModel_VehicleModel_ConditionCheckRead
        DataServices_VehicleModel_VehicleModel_ReadData
        RoutineServices_ResetSwitchStatistics_Start
        RoutineServices_PhyTestMode_Start
        RoutineServices_AVMEnvironmentCheck_RequestResults
        RoutineServices_AVMEnvironmentCheck_Start
        RoutineServices_AVMManualConerMove_RequestResults
        RoutineServices_AVMManualConerMove_Start
        RoutineServices_AVMManualConerSelect_RequestResults
        RoutineServices_AVMManualConerSelect_Start
        RoutineServices_AVMManualCorrectValue_RequestResults
        RoutineServices_AVMManualCorrectValue_Start
        RoutineServices_AVMManualViewSelect_RequestResults
        RoutineServices_AVMManualViewSelect_Start
        RoutineServices_AVMAutoCalibration_RequestResults
        RoutineServices_AVMAutoCalibration_Start
        NvMNotifyJobFinished_NvBlockNeed_ClusterInternalConfiguration_JobFinished
        AppGetVinNumberFunction
        ppCS_Diag_WriteDidData_Operation: can-be-invoked-concurrently=true
        ppCS_Diag_ReadDidData_Operation: can-be-invoked-concurrently=true
        NvMNotifyJobFinished_NvBlockNeed_E2ESwitch_JobFinished
        NvMNotifyJobFinished_NvBlockNeed_SecOcSwitch_JobFinished
        RoutineServices_SystemRecovery_Start
        GetCANMatrixVersionInfo_Data
        GetVehicleModeInfo_Data
        RoutineServices_ODOReset_RequestResults
        RoutineServices_ODOReset_Start
        RoutineServices_CableDiagnostics_Start
        RoutineServices_AVMManualCalibration_Stop
        RoutineServices_AVMManualCalibration_RequestResults
        RoutineServices_AVMManualCalibration_Start
        SecOcSwitchStatusRead
        SecOcSwitchStatusWrite
        E2ESwitchStatusRead
        E2ESwitchStatusWrite
        ppCS_USBWriteECUlevelNetworkConfigurationData_USBWriteData
        NvMNotifyJobFinished_NvBlockNeed_VehicleSoftwareVersion_JobFinished
        RoutineServices_ConfigureRightCamerParameters_RequestResults
        RoutineServices_ConfigureRightCamerParameters_Start
        RoutineServices_ConfigureRearCamerParameters_RequestResults
        RoutineServices_ConfigureRearCamerParameters_Start
        RoutineServices_ConfigureLeftCamerParameters_RequestResults
        RoutineServices_ConfigureLeftCamerParameters_Start
        RoutineServices_ConfigureFrontCamerParameters_RequestResults
        RoutineServices_ConfigureFrontCamerParameters_Start
        DataServices_DIDRange_DidRangeDiag2_IsDidAvailable
        DataServices_DIDRange_DidRangeDiag2_WriteDidData
        DataServices_DIDRange_DidRangeDiag2_ReadDidData
          5 x sync call:
            SC_TC_Api_ParamentGetCsPort_Operation: operation=TC_Api_ParamentGetCsPort.Operation
            SC_cpCS_OdoSetParament_Operation: operation=cpCS_OdoSetParament.Operation
            SC_ppCS_GetTankResistanceValue_Operation: operation=ppCS_GetTankResistanceValue.Operation
            SC_rpCS_Fuel_Api_ParamentGetCsPort_Operation: operation=rpCS_Fuel_Api_ParamentGetCsPort.Operation
            SC_rpCS_Odo_Api_ParamentGetCsPort_Operation: operation=rpCS_Odo_Api_ParamentGetCsPort.Operation
        DataServices_DIDRange_DidRangeDiag1_IsDidAvailable
        DataServices_DIDRange_DidRangeDiag1_WriteDidData
        DataServices_DIDRange_DidRangeDiag1_ReadDidData
        NvMNotifyJobFinished_NvBlockNeed_ClusterDisplayHMIAdjustmentOffset_JobFinished
        RoutineServices_RequestCertificateStatus_RequestResults
        RoutineServices_RequestCertificateStatus_Start
      10 x swc service dependency:
        NvBlockNeed_VIN
          assigned-datas:
            role=ramBlock, used-data-element=NvBlockNeed_VIN_MirrorBlock
            role=defaultValue, used-parameter-element=NvBlockNeed_VIN_DefaultValue
            role=defaultValue, used-parameter-element=NvBlockNeed_VIN_DefaultValue
            role=defaultValue, used-parameter-element=NvBlockNeed_VIN_DefaultValue
            role=defaultValue, used-parameter-element=NvBlockNeed_VIN_DefaultValue
            role=defaultValue, used-parameter-element=NvBlockNeed_VIN_DefaultValue
            role=defaultValue, used-parameter-element=NvBlockNeed_VIN_DefaultValue
            role=defaultValue, used-parameter-element=NvBlockNeed_VIN_DefaultValue
            role=defaultValue, used-parameter-element=NvBlockNeed_VIN_DefaultValue
            role=defaultValue, used-parameter-element=NvBlockNeed_VIN_DefaultValue
            role=defaultValue, used-parameter-element=NvBlockNeed_VIN_DefaultValue
            role=defaultValue, used-parameter-element=NvBlockNeed_VIN_DefaultValue
            role=defaultValue, used-parameter-element=NvBlockNeed_VIN_DefaultValue
            role=defaultValue, used-parameter-element=NvBlockNeed_VIN_DefaultValue
            role=defaultValue, used-parameter-element=NvBlockNeed_VIN_DefaultValue
            role=defaultValue, used-parameter-element=NvBlockNeed_VIN_DefaultValue
            role=defaultValue, used-parameter-element=NvBlockNeed_VIN_DefaultValue
            role=defaultValue, used-parameter-element=NvBlockNeed_VIN_DefaultValue
            role=defaultValue, used-parameter-element=NvBlockNeed_VIN_DefaultValue
            role=defaultValue, used-parameter-element=NvBlockNeed_VIN_DefaultValue
            role=defaultValue, used-parameter-element=NvBlockNeed_VIN_DefaultValue
            role=defaultValue, used-parameter-element=NvBlockNeed_VIN_DefaultValue
            role=defaultValue, used-parameter-element=NvBlockNeed_VIN_DefaultValue
            role=defaultValue, used-parameter-element=NvBlockNeed_VIN_DefaultValue
            role=defaultValue, used-parameter-element=NvBlockNeed_VIN_DefaultValue
            role=defaultValue, used-parameter-element=NvBlockNeed_VIN_DefaultValue
            role=defaultValue, used-parameter-element=NvBlockNeed_VIN_DefaultValue
            role=defaultValue, used-parameter-element=NvBlockNeed_VIN_DefaultValue
            role=defaultValue, used-parameter-element=NvBlockNeed_VIN_DefaultValue
            role=defaultValue, used-parameter-element=NvBlockNeed_VIN_DefaultValue
            role=defaultValue, used-parameter-element=NvBlockNeed_VIN_DefaultValue
            role=defaultValue, used-parameter-element=NvBlockNeed_VIN_DefaultValue
            role=defaultValue, used-parameter-element=NvBlockNeed_VIN_DefaultValue
            role=defaultValue, used-parameter-element=NvBlockNeed_VIN_DefaultValue
            role=defaultValue, used-parameter-element=NvBlockNeed_VIN_DefaultValue
            role=defaultValue, used-parameter-element=NvBlockNeed_VIN_DefaultValue
            role=defaultValue, used-parameter-element=NvBlockNeed_VIN_DefaultValue
            role=defaultValue, used-parameter-element=NvBlockNeed_VIN_DefaultValue
            role=defaultValue, used-parameter-element=NvBlockNeed_VIN_DefaultValue
            role=defaultValue, used-parameter-element=NvBlockNeed_VIN_DefaultValue
            role=defaultValue, used-parameter-element=NvBlockNeed_VIN_DefaultValue
            role=defaultValue, used-parameter-element=NvBlockNeed_VIN_DefaultValue
            role=defaultValue, used-parameter-element=NvBlockNeed_VIN_DefaultValue
            role=defaultValue, used-parameter-element=NvBlockNeed_VIN_DefaultValue
            role=defaultValue, used-parameter-element=NvBlockNeed_VIN_DefaultValue
            role=defaultValue, used-parameter-element=NvBlockNeed_VIN_DefaultValue
            role=defaultValue, used-parameter-element=NvBlockNeed_VIN_DefaultValue
            role=defaultValue, used-parameter-element=NvBlockNeed_VIN_DefaultValue
            role=defaultValue, used-parameter-element=NvBlockNeed_VIN_DefaultValue
            role=defaultValue, used-parameter-element=NvBlockNeed_VIN_DefaultValue
            role=defaultValue, used-parameter-element=NvBlockNeed_VIN_DefaultValue
            role=defaultValue, used-parameter-element=NvBlockNeed_VIN_DefaultValue
            role=defaultValue, used-parameter-element=NvBlockNeed_VIN_DefaultValue
            role=defaultValue, used-parameter-element=NvBlockNeed_VIN_DefaultValue
            role=defaultValue, used-parameter-element=NvBlockNeed_VIN_DefaultValue
            role=defaultValue, used-parameter-element=NvBlockNeed_VIN_DefaultValue
            role=defaultValue, used-parameter-element=NvBlockNeed_VIN_DefaultValue
            role=defaultValue, used-parameter-element=NvBlockNeed_VIN_DefaultValue
            role=defaultValue, used-parameter-element=NvBlockNeed_VIN_DefaultValue
            role=defaultValue, used-parameter-element=NvBlockNeed_VIN_DefaultValue
            role=defaultValue, used-parameter-element=NvBlockNeed_VIN_DefaultValue
            role=defaultValue, used-parameter-element=NvBlockNeed_VIN_DefaultValue
            role=defaultValue, used-parameter-element=NvBlockNeed_VIN_DefaultValue
            role=defaultValue, used-parameter-element=NvBlockNeed_VIN_DefaultValue
            role=defaultValue, used-parameter-element=NvBlockNeed_VIN_DefaultValue
            role=defaultValue, used-parameter-element=NvBlockNeed_VIN_DefaultValue
            role=defaultValue, used-parameter-element=NvBlockNeed_VIN_DefaultValue
            role=defaultValue, used-parameter-element=NvBlockNeed_VIN_DefaultValue
            role=defaultValue, used-parameter-element=NvBlockNeed_VIN_DefaultValue
            role=defaultValue, used-parameter-element=NvBlockNeed_VIN_DefaultValue
            role=defaultValue, used-parameter-element=NvBlockNeed_VIN_DefaultValue
            role=defaultValue, used-parameter-element=NvBlockNeed_VIN_DefaultValue
            role=defaultValue, used-parameter-element=NvBlockNeed_VIN_DefaultValue
            role=defaultValue, used-parameter-element=NvBlockNeed_VIN_DefaultValue
            role=defaultValue, used-parameter-element=NvBlockNeed_VIN_DefaultValue
            role=defaultValue, used-parameter-element=NvBlockNeed_VIN_DefaultValue
            role=defaultValue, used-parameter-element=NvBlockNeed_VIN_DefaultValue
            role=defaultValue, used-parameter-element=NvBlockNeed_VIN_DefaultValue
            role=defaultValue, used-parameter-element=NvBlockNeed_VIN_DefaultValue
            role=defaultValue, used-parameter-element=NvBlockNeed_VIN_DefaultValue
            role=defaultValue, used-parameter-element=NvBlockNeed_VIN_DefaultValue
            role=defaultValue, used-parameter-element=NvBlockNeed_VIN_DefaultValue
            role=defaultValue, used-parameter-element=NvBlockNeed_VIN_DefaultValue
            role=defaultValue, used-parameter-element=NvBlockNeed_VIN_DefaultValue
            role=defaultValue, used-parameter-element=NvBlockNeed_VIN_DefaultValue
            role=defaultValue, used-parameter-element=NvBlockNeed_VIN_DefaultValue
            role=defaultValue, used-parameter-element=NvBlockNeed_VIN_DefaultValue
            role=defaultValue, used-parameter-element=NvBlockNeed_VIN_DefaultValue
            role=defaultValue, used-parameter-element=NvBlockNeed_VIN_DefaultValue
            role=defaultValue, used-parameter-element=NvBlockNeed_VIN_DefaultValue
            role=defaultValue, used-parameter-element=NvBlockNeed_VIN_DefaultValue
            role=defaultValue, used-parameter-element=NvBlockNeed_VIN_DefaultValue
            role=defaultValue, used-parameter-element=NvBlockNeed_VIN_DefaultValue
            role=defaultValue, used-parameter-element=NvBlockNeed_VIN_DefaultValue
            role=defaultValue, used-parameter-element=NvBlockNeed_VIN_DefaultValue
            role=defaultValue, used-parameter-element=NvBlockNeed_VIN_DefaultValue
            role=defaultValue, used-parameter-element=NvBlockNeed_VIN_DefaultValue
            role=defaultValue, used-parameter-element=NvBlockNeed_VIN_DefaultValue
            role=defaultValue, used-parameter-element=NvBlockNeed_VIN_DefaultValue
            role=defaultValue, used-parameter-element=NvBlockNeed_VIN_DefaultValue
            role=defaultValue, used-parameter-element=NvBlockNeed_VIN_DefaultValue
            role=defaultValue, used-parameter-element=NvBlockNeed_VIN_DefaultValue
            role=defaultValue, used-parameter-element=NvBlockNeed_VIN_DefaultValue
            role=defaultValue, used-parameter-element=NvBlockNeed_VIN_DefaultValue
            role=defaultValue, used-parameter-element=NvBlockNeed_VIN_DefaultValue
            role=defaultValue, used-parameter-element=NvBlockNeed_VIN_DefaultValue
            role=defaultValue, used-parameter-element=NvBlockNeed_VIN_DefaultValue
            role=defaultValue, used-parameter-element=NvBlockNeed_VIN_DefaultValue
            role=defaultValue, used-parameter-element=NvBlockNeed_VIN_DefaultValue
            role=defaultValue, used-parameter-element=NvBlockNeed_VIN_DefaultValue
            role=defaultValue, used-parameter-element=NvBlockNeed_VIN_DefaultValue
            role=defaultValue, used-parameter-element=NvBlockNeed_VIN_DefaultValue
            role=defaultValue, used-parameter-element=NvBlockNeed_VIN_DefaultValue
            role=defaultValue, used-parameter-element=NvBlockNeed_VIN_DefaultValue
            role=defaultValue, used-parameter-element=NvBlockNeed_VIN_DefaultValue
            role=defaultValue, used-parameter-element=NvBlockNeed_VIN_DefaultValue
            role=defaultValue, used-parameter-element=NvBlockNeed_VIN_DefaultValue
            role=defaultValue, used-parameter-element=NvBlockNeed_VIN_DefaultValue
            role=defaultValue, used-parameter-element=NvBlockNeed_VIN_DefaultValue
            role=defaultValue, used-parameter-element=NvBlockNeed_VIN_DefaultValue
            role=defaultValue, used-parameter-element=NvBlockNeed_VIN_DefaultValue
            role=defaultValue, used-parameter-element=NvBlockNeed_VIN_DefaultValue
            role=defaultValue, used-parameter-element=NvBlockNeed_VIN_DefaultValue
            role=defaultValue, used-parameter-element=NvBlockNeed_VIN_DefaultValue
            role=defaultValue, used-parameter-element=NvBlockNeed_VIN_DefaultValue
            role=defaultValue, used-parameter-element=NvBlockNeed_VIN_DefaultValue
            role=defaultValue, used-parameter-element=NvBlockNeed_VIN_DefaultValue
            role=defaultValue, used-parameter-element=NvBlockNeed_VIN_DefaultValue
            role=defaultValue, used-parameter-element=NvBlockNeed_VIN_DefaultValue
          assigned-ports:
            port-prototype=NvMNotifyJobFinished_NvBlockNeed_VIN, role=NvMNotifyJobFinished
            port-prototype=NvMService_AC2_SRBS_NvBlockNeed_VIN, role=NvMService_AC2_SRBS
          service-needs:
            nv block needs NvBlockNeed_VIN: n-data-sets=0, ram-block-status-control=API, reliability=NO-PROTECTION, restore-at-start=true, store-at-shutdown=true
        NvBlockNeed_VehicleMode
          assigned-datas:
            role=ramBlock, used-data-element=NvBlockNeed_VehicleMode_MirrorBlock
            role=defaultValue, used-parameter-element=NvBlockNeed_VehicleMode_DefaultValue
            role=defaultValue, used-parameter-element=NvBlockNeed_VehicleMode_DefaultValue
            role=defaultValue, used-parameter-element=NvBlockNeed_VehicleMode_DefaultValue
            role=defaultValue, used-parameter-element=NvBlockNeed_VehicleMode_DefaultValue
            role=defaultValue, used-parameter-element=NvBlockNeed_VehicleMode_DefaultValue
            role=defaultValue, used-parameter-element=NvBlockNeed_VehicleMode_DefaultValue
            role=defaultValue, used-parameter-element=NvBlockNeed_VehicleMode_DefaultValue
            role=defaultValue, used-parameter-element=NvBlockNeed_VehicleMode_DefaultValue
            role=defaultValue, used-parameter-element=NvBlockNeed_VehicleMode_DefaultValue
            role=defaultValue, used-parameter-element=NvBlockNeed_VehicleMode_DefaultValue
            role=defaultValue, used-parameter-element=NvBlockNeed_VehicleMode_DefaultValue
            role=defaultValue, used-parameter-element=NvBlockNeed_VehicleMode_DefaultValue
            role=defaultValue, used-parameter-element=NvBlockNeed_VehicleMode_DefaultValue
            role=defaultValue, used-parameter-element=NvBlockNeed_VehicleMode_DefaultValue
            role=defaultValue, used-parameter-element=NvBlockNeed_VehicleMode_DefaultValue
            role=defaultValue, used-parameter-element=NvBlockNeed_VehicleMode_DefaultValue
            role=defaultValue, used-parameter-element=NvBlockNeed_VehicleMode_DefaultValue
            role=defaultValue, used-parameter-element=NvBlockNeed_VehicleMode_DefaultValue
            role=defaultValue, used-parameter-element=NvBlockNeed_VehicleMode_DefaultValue
            role=defaultValue, used-parameter-element=NvBlockNeed_VehicleMode_DefaultValue
            role=defaultValue, used-parameter-element=NvBlockNeed_VehicleMode_DefaultValue
            role=defaultValue, used-parameter-element=NvBlockNeed_VehicleMode_DefaultValue
            role=defaultValue, used-parameter-element=NvBlockNeed_VehicleMode_DefaultValue
            role=defaultValue, used-parameter-element=NvBlockNeed_VehicleMode_DefaultValue
            role=defaultValue, used-parameter-element=NvBlockNeed_VehicleMode_DefaultValue
            role=defaultValue, used-parameter-element=NvBlockNeed_VehicleMode_DefaultValue
            role=defaultValue, used-parameter-element=NvBlockNeed_VehicleMode_DefaultValue
            role=defaultValue, used-parameter-element=NvBlockNeed_VehicleMode_DefaultValue
            role=defaultValue, used-parameter-element=NvBlockNeed_VehicleMode_DefaultValue
            role=defaultValue, used-parameter-element=NvBlockNeed_VehicleMode_DefaultValue
            role=defaultValue, used-parameter-element=NvBlockNeed_VehicleMode_DefaultValue
            role=defaultValue, used-parameter-element=NvBlockNeed_VehicleMode_DefaultValue
            role=defaultValue, used-parameter-element=NvBlockNeed_VehicleMode_DefaultValue
            role=defaultValue, used-parameter-element=NvBlockNeed_VehicleMode_DefaultValue
            role=defaultValue, used-parameter-element=NvBlockNeed_VehicleMode_DefaultValue
            role=defaultValue, used-parameter-element=NvBlockNeed_VehicleMode_DefaultValue
            role=defaultValue, used-parameter-element=NvBlockNeed_VehicleMode_DefaultValue
            role=defaultValue, used-parameter-element=NvBlockNeed_VehicleMode_DefaultValue
            role=defaultValue, used-parameter-element=NvBlockNeed_VehicleMode_DefaultValue
            role=defaultValue, used-parameter-element=NvBlockNeed_VehicleMode_DefaultValue
            role=defaultValue, used-parameter-element=NvBlockNeed_VehicleMode_DefaultValue
            role=defaultValue, used-parameter-element=NvBlockNeed_VehicleMode_DefaultValue
            role=defaultValue, used-parameter-element=NvBlockNeed_VehicleMode_DefaultValue
            role=defaultValue, used-parameter-element=NvBlockNeed_VehicleMode_DefaultValue
            role=defaultValue, used-parameter-element=NvBlockNeed_VehicleMode_DefaultValue
            role=defaultValue, used-parameter-element=NvBlockNeed_VehicleMode_DefaultValue
            role=defaultValue, used-parameter-element=NvBlockNeed_VehicleMode_DefaultValue
            role=defaultValue, used-parameter-element=NvBlockNeed_VehicleMode_DefaultValue
            role=defaultValue, used-parameter-element=NvBlockNeed_VehicleMode_DefaultValue
            role=defaultValue, used-parameter-element=NvBlockNeed_VehicleMode_DefaultValue
            role=defaultValue, used-parameter-element=NvBlockNeed_VehicleMode_DefaultValue
            role=defaultValue, used-parameter-element=NvBlockNeed_VehicleMode_DefaultValue
            role=defaultValue, used-parameter-element=NvBlockNeed_VehicleMode_DefaultValue
            role=defaultValue, used-parameter-element=NvBlockNeed_VehicleMode_DefaultValue
            role=defaultValue, used-parameter-element=NvBlockNeed_VehicleMode_DefaultValue
            role=defaultValue, used-parameter-element=NvBlockNeed_VehicleMode_DefaultValue
            role=defaultValue, used-parameter-element=NvBlockNeed_VehicleMode_DefaultValue
            role=defaultValue, used-parameter-element=NvBlockNeed_VehicleMode_DefaultValue
            role=defaultValue, used-parameter-element=NvBlockNeed_VehicleMode_DefaultValue
            role=defaultValue, used-parameter-element=NvBlockNeed_VehicleMode_DefaultValue
            role=defaultValue, used-parameter-element=NvBlockNeed_VehicleMode_DefaultValue
            role=defaultValue, used-parameter-element=NvBlockNeed_VehicleMode_DefaultValue
            role=defaultValue, used-parameter-element=NvBlockNeed_VehicleMode_DefaultValue
            role=defaultValue, used-parameter-element=NvBlockNeed_VehicleMode_DefaultValue
            role=defaultValue, used-parameter-element=NvBlockNeed_VehicleMode_DefaultValue
            role=defaultValue, used-parameter-element=NvBlockNeed_VehicleMode_DefaultValue
            role=defaultValue, used-parameter-element=NvBlockNeed_VehicleMode_DefaultValue
            role=defaultValue, used-parameter-element=NvBlockNeed_VehicleMode_DefaultValue
            role=defaultValue, used-parameter-element=NvBlockNeed_VehicleMode_DefaultValue
            role=defaultValue, used-parameter-element=NvBlockNeed_VehicleMode_DefaultValue
            role=defaultValue, used-parameter-element=NvBlockNeed_VehicleMode_DefaultValue
            role=defaultValue, used-parameter-element=NvBlockNeed_VehicleMode_DefaultValue
            role=defaultValue, used-parameter-element=NvBlockNeed_VehicleMode_DefaultValue
            role=defaultValue, used-parameter-element=NvBlockNeed_VehicleMode_DefaultValue
            role=defaultValue, used-parameter-element=NvBlockNeed_VehicleMode_DefaultValue
            role=defaultValue, used-parameter-element=NvBlockNeed_VehicleMode_DefaultValue
            role=defaultValue, used-parameter-element=NvBlockNeed_VehicleMode_DefaultValue
            role=defaultValue, used-parameter-element=NvBlockNeed_VehicleMode_DefaultValue
            role=defaultValue, used-parameter-element=NvBlockNeed_VehicleMode_DefaultValue
            role=defaultValue, used-parameter-element=NvBlockNeed_VehicleMode_DefaultValue
            role=defaultValue, used-parameter-element=NvBlockNeed_VehicleMode_DefaultValue
            role=defaultValue, used-parameter-element=NvBlockNeed_VehicleMode_DefaultValue
            role=defaultValue, used-parameter-element=NvBlockNeed_VehicleMode_DefaultValue
            role=defaultValue, used-parameter-element=NvBlockNeed_VehicleMode_DefaultValue
            role=defaultValue, used-parameter-element=NvBlockNeed_VehicleMode_DefaultValue
            role=defaultValue, used-parameter-element=NvBlockNeed_VehicleMode_DefaultValue
            role=defaultValue, used-parameter-element=NvBlockNeed_VehicleMode_DefaultValue
            role=defaultValue, used-parameter-element=NvBlockNeed_VehicleMode_DefaultValue
            role=defaultValue, used-parameter-element=NvBlockNeed_VehicleMode_DefaultValue
            role=defaultValue, used-parameter-element=NvBlockNeed_VehicleMode_DefaultValue
            role=defaultValue, used-parameter-element=NvBlockNeed_VehicleMode_DefaultValue
            role=defaultValue, used-parameter-element=NvBlockNeed_VehicleMode_DefaultValue
            role=defaultValue, used-parameter-element=NvBlockNeed_VehicleMode_DefaultValue
            role=defaultValue, used-parameter-element=NvBlockNeed_VehicleMode_DefaultValue
            role=defaultValue, used-parameter-element=NvBlockNeed_VehicleMode_DefaultValue
            role=defaultValue, used-parameter-element=NvBlockNeed_VehicleMode_DefaultValue
            role=defaultValue, used-parameter-element=NvBlockNeed_VehicleMode_DefaultValue
            role=defaultValue, used-parameter-element=NvBlockNeed_VehicleMode_DefaultValue
            role=defaultValue, used-parameter-element=NvBlockNeed_VehicleMode_DefaultValue
            role=defaultValue, used-parameter-element=NvBlockNeed_VehicleMode_DefaultValue
            role=defaultValue, used-parameter-element=NvBlockNeed_VehicleMode_DefaultValue
            role=defaultValue, used-parameter-element=NvBlockNeed_VehicleMode_DefaultValue
            role=defaultValue, used-parameter-element=NvBlockNeed_VehicleMode_DefaultValue
            role=defaultValue, used-parameter-element=NvBlockNeed_VehicleMode_DefaultValue
            role=defaultValue, used-parameter-element=NvBlockNeed_VehicleMode_DefaultValue
            role=defaultValue, used-parameter-element=NvBlockNeed_VehicleMode_DefaultValue
            role=defaultValue, used-parameter-element=NvBlockNeed_VehicleMode_DefaultValue
            role=defaultValue, used-parameter-element=NvBlockNeed_VehicleMode_DefaultValue
            role=defaultValue, used-parameter-element=NvBlockNeed_VehicleMode_DefaultValue
            role=defaultValue, used-parameter-element=NvBlockNeed_VehicleMode_DefaultValue
            role=defaultValue, used-parameter-element=NvBlockNeed_VehicleMode_DefaultValue
            role=defaultValue, used-parameter-element=NvBlockNeed_VehicleMode_DefaultValue
            role=defaultValue, used-parameter-element=NvBlockNeed_VehicleMode_DefaultValue
            role=defaultValue, used-parameter-element=NvBlockNeed_VehicleMode_DefaultValue
            role=defaultValue, used-parameter-element=NvBlockNeed_VehicleMode_DefaultValue
            role=defaultValue, used-parameter-element=NvBlockNeed_VehicleMode_DefaultValue
            role=defaultValue, used-parameter-element=NvBlockNeed_VehicleMode_DefaultValue
            role=defaultValue, used-parameter-element=NvBlockNeed_VehicleMode_DefaultValue
            role=defaultValue, used-parameter-element=NvBlockNeed_VehicleMode_DefaultValue
            role=defaultValue, used-parameter-element=NvBlockNeed_VehicleMode_DefaultValue
            role=defaultValue, used-parameter-element=NvBlockNeed_VehicleMode_DefaultValue
            role=defaultValue, used-parameter-element=NvBlockNeed_VehicleMode_DefaultValue
            role=defaultValue, used-parameter-element=NvBlockNeed_VehicleMode_DefaultValue
            role=defaultValue, used-parameter-element=NvBlockNeed_VehicleMode_DefaultValue
            role=defaultValue, used-parameter-element=NvBlockNeed_VehicleMode_DefaultValue
            role=defaultValue, used-parameter-element=NvBlockNeed_VehicleMode_DefaultValue
            role=defaultValue, used-parameter-element=NvBlockNeed_VehicleMode_DefaultValue
            role=defaultValue, used-parameter-element=NvBlockNeed_VehicleMode_DefaultValue
          assigned-ports:
            port-prototype=NvMNotifyJobFinished_NvBlockNeed_VehicleMode, role=NvMNotifyJobFinished
            port-prototype=NvMService_AC2_SRBS_NvBlockNeed_VehicleMode, role=NvMService_AC2_SRBS
          service-needs:
            nv block needs NvBlockNeed_VehicleMode: n-data-sets=0, ram-block-status-control=API, reliability=NO-PROTECTION, restore-at-start=true, store-at-shutdown=true
        NvBlockNeed_FactoryMode
          assigned-datas:
            role=ramBlock, used-data-element=NvBlockNeed_FactoryMode_MirrorBlock
            role=defaultValue, used-parameter-element=NvBlockNeed_FactoryMode_DefaultValue
            role=defaultValue, used-parameter-element=NvBlockNeed_FactoryMode_DefaultValue
            role=defaultValue, used-parameter-element=NvBlockNeed_FactoryMode_DefaultValue
            role=defaultValue, used-parameter-element=NvBlockNeed_FactoryMode_DefaultValue
            role=defaultValue, used-parameter-element=NvBlockNeed_FactoryMode_DefaultValue
            role=defaultValue, used-parameter-element=NvBlockNeed_FactoryMode_DefaultValue
            role=defaultValue, used-parameter-element=NvBlockNeed_FactoryMode_DefaultValue
            role=defaultValue, used-parameter-element=NvBlockNeed_FactoryMode_DefaultValue
            role=defaultValue, used-parameter-element=NvBlockNeed_FactoryMode_DefaultValue
            role=defaultValue, used-parameter-element=NvBlockNeed_FactoryMode_DefaultValue
            role=defaultValue, used-parameter-element=NvBlockNeed_FactoryMode_DefaultValue
            role=defaultValue, used-parameter-element=NvBlockNeed_FactoryMode_DefaultValue
            role=defaultValue, used-parameter-element=NvBlockNeed_FactoryMode_DefaultValue
            role=defaultValue, used-parameter-element=NvBlockNeed_FactoryMode_DefaultValue
            role=defaultValue, used-parameter-element=NvBlockNeed_FactoryMode_DefaultValue
            role=defaultValue, used-parameter-element=NvBlockNeed_FactoryMode_DefaultValue
            role=defaultValue, used-parameter-element=NvBlockNeed_FactoryMode_DefaultValue
            role=defaultValue, used-parameter-element=NvBlockNeed_FactoryMode_DefaultValue
            role=defaultValue, used-parameter-element=NvBlockNeed_FactoryMode_DefaultValue
            role=defaultValue, used-parameter-element=NvBlockNeed_FactoryMode_DefaultValue
            role=defaultValue, used-parameter-element=NvBlockNeed_FactoryMode_DefaultValue
            role=defaultValue, used-parameter-element=NvBlockNeed_FactoryMode_DefaultValue
            role=defaultValue, used-parameter-element=NvBlockNeed_FactoryMode_DefaultValue
            role=defaultValue, used-parameter-element=NvBlockNeed_FactoryMode_DefaultValue
            role=defaultValue, used-parameter-element=NvBlockNeed_FactoryMode_DefaultValue
            role=defaultValue, used-parameter-element=NvBlockNeed_FactoryMode_DefaultValue
            role=defaultValue, used-parameter-element=NvBlockNeed_FactoryMode_DefaultValue
            role=defaultValue, used-parameter-element=NvBlockNeed_FactoryMode_DefaultValue
            role=defaultValue, used-parameter-element=NvBlockNeed_FactoryMode_DefaultValue
            role=defaultValue, used-parameter-element=NvBlockNeed_FactoryMode_DefaultValue
            role=defaultValue, used-parameter-element=NvBlockNeed_FactoryMode_DefaultValue
            role=defaultValue, used-parameter-element=NvBlockNeed_FactoryMode_DefaultValue
            role=defaultValue, used-parameter-element=NvBlockNeed_FactoryMode_DefaultValue
            role=defaultValue, used-parameter-element=NvBlockNeed_FactoryMode_DefaultValue
            role=defaultValue, used-parameter-element=NvBlockNeed_FactoryMode_DefaultValue
            role=defaultValue, used-parameter-element=NvBlockNeed_FactoryMode_DefaultValue
            role=defaultValue, used-parameter-element=NvBlockNeed_FactoryMode_DefaultValue
            role=defaultValue, used-parameter-element=NvBlockNeed_FactoryMode_DefaultValue
            role=defaultValue, used-parameter-element=NvBlockNeed_FactoryMode_DefaultValue
            role=defaultValue, used-parameter-element=NvBlockNeed_FactoryMode_DefaultValue
            role=defaultValue, used-parameter-element=NvBlockNeed_FactoryMode_DefaultValue
            role=defaultValue, used-parameter-element=NvBlockNeed_FactoryMode_DefaultValue
            role=defaultValue, used-parameter-element=NvBlockNeed_FactoryMode_DefaultValue
            role=defaultValue, used-parameter-element=NvBlockNeed_FactoryMode_DefaultValue
            role=defaultValue, used-parameter-element=NvBlockNeed_FactoryMode_DefaultValue
            role=defaultValue, used-parameter-element=NvBlockNeed_FactoryMode_DefaultValue
            role=defaultValue, used-parameter-element=NvBlockNeed_FactoryMode_DefaultValue
            role=defaultValue, used-parameter-element=NvBlockNeed_FactoryMode_DefaultValue
            role=defaultValue, used-parameter-element=NvBlockNeed_FactoryMode_DefaultValue
            role=defaultValue, used-parameter-element=NvBlockNeed_FactoryMode_DefaultValue
            role=defaultValue, used-parameter-element=NvBlockNeed_FactoryMode_DefaultValue
            role=defaultValue, used-parameter-element=NvBlockNeed_FactoryMode_DefaultValue
            role=defaultValue, used-parameter-element=NvBlockNeed_FactoryMode_DefaultValue
            role=defaultValue, used-parameter-element=NvBlockNeed_FactoryMode_DefaultValue
            role=defaultValue, used-parameter-element=NvBlockNeed_FactoryMode_DefaultValue
            role=defaultValue, used-parameter-element=NvBlockNeed_FactoryMode_DefaultValue
            role=defaultValue, used-parameter-element=NvBlockNeed_FactoryMode_DefaultValue
            role=defaultValue, used-parameter-element=NvBlockNeed_FactoryMode_DefaultValue
            role=defaultValue, used-parameter-element=NvBlockNeed_FactoryMode_DefaultValue
            role=defaultValue, used-parameter-element=NvBlockNeed_FactoryMode_DefaultValue
            role=defaultValue, used-parameter-element=NvBlockNeed_FactoryMode_DefaultValue
            role=defaultValue, used-parameter-element=NvBlockNeed_FactoryMode_DefaultValue
            role=defaultValue, used-parameter-element=NvBlockNeed_FactoryMode_DefaultValue
            role=defaultValue, used-parameter-element=NvBlockNeed_FactoryMode_DefaultValue
            role=defaultValue, used-parameter-element=NvBlockNeed_FactoryMode_DefaultValue
            role=defaultValue, used-parameter-element=NvBlockNeed_FactoryMode_DefaultValue
            role=defaultValue, used-parameter-element=NvBlockNeed_FactoryMode_DefaultValue
            role=defaultValue, used-parameter-element=NvBlockNeed_FactoryMode_DefaultValue
            role=defaultValue, used-parameter-element=NvBlockNeed_FactoryMode_DefaultValue
            role=defaultValue, used-parameter-element=NvBlockNeed_FactoryMode_DefaultValue
            role=defaultValue, used-parameter-element=NvBlockNeed_FactoryMode_DefaultValue
            role=defaultValue, used-parameter-element=NvBlockNeed_FactoryMode_DefaultValue
            role=defaultValue, used-parameter-element=NvBlockNeed_FactoryMode_DefaultValue
            role=defaultValue, used-parameter-element=NvBlockNeed_FactoryMode_DefaultValue
            role=defaultValue, used-parameter-element=NvBlockNeed_FactoryMode_DefaultValue
            role=defaultValue, used-parameter-element=NvBlockNeed_FactoryMode_DefaultValue
            role=defaultValue, used-parameter-element=NvBlockNeed_FactoryMode_DefaultValue
            role=defaultValue, used-parameter-element=NvBlockNeed_FactoryMode_DefaultValue
            role=defaultValue, used-parameter-element=NvBlockNeed_FactoryMode_DefaultValue
            role=defaultValue, used-parameter-element=NvBlockNeed_FactoryMode_DefaultValue
            role=defaultValue, used-parameter-element=NvBlockNeed_FactoryMode_DefaultValue
            role=defaultValue, used-parameter-element=NvBlockNeed_FactoryMode_DefaultValue
            role=defaultValue, used-parameter-element=NvBlockNeed_FactoryMode_DefaultValue
            role=defaultValue, used-parameter-element=NvBlockNeed_FactoryMode_DefaultValue
            role=defaultValue, used-parameter-element=NvBlockNeed_FactoryMode_DefaultValue
            role=defaultValue, used-parameter-element=NvBlockNeed_FactoryMode_DefaultValue
            role=defaultValue, used-parameter-element=NvBlockNeed_FactoryMode_DefaultValue
            role=defaultValue, used-parameter-element=NvBlockNeed_FactoryMode_DefaultValue
            role=defaultValue, used-parameter-element=NvBlockNeed_FactoryMode_DefaultValue
            role=defaultValue, used-parameter-element=NvBlockNeed_FactoryMode_DefaultValue
            role=defaultValue, used-parameter-element=NvBlockNeed_FactoryMode_DefaultValue
            role=defaultValue, used-parameter-element=NvBlockNeed_FactoryMode_DefaultValue
            role=defaultValue, used-parameter-element=NvBlockNeed_FactoryMode_DefaultValue
            role=defaultValue, used-parameter-element=NvBlockNeed_FactoryMode_DefaultValue
            role=defaultValue, used-parameter-element=NvBlockNeed_FactoryMode_DefaultValue
            role=defaultValue, used-parameter-element=NvBlockNeed_FactoryMode_DefaultValue
            role=defaultValue, used-parameter-element=NvBlockNeed_FactoryMode_DefaultValue
            role=defaultValue, used-parameter-element=NvBlockNeed_FactoryMode_DefaultValue
            role=defaultValue, used-parameter-element=NvBlockNeed_FactoryMode_DefaultValue
            role=defaultValue, used-parameter-element=NvBlockNeed_FactoryMode_DefaultValue
            role=defaultValue, used-parameter-element=NvBlockNeed_FactoryMode_DefaultValue
            role=defaultValue, used-parameter-element=NvBlockNeed_FactoryMode_DefaultValue
            role=defaultValue, used-parameter-element=NvBlockNeed_FactoryMode_DefaultValue
            role=defaultValue, used-parameter-element=NvBlockNeed_FactoryMode_DefaultValue
            role=defaultValue, used-parameter-element=NvBlockNeed_FactoryMode_DefaultValue
            role=defaultValue, used-parameter-element=NvBlockNeed_FactoryMode_DefaultValue
            role=defaultValue, used-parameter-element=NvBlockNeed_FactoryMode_DefaultValue
            role=defaultValue, used-parameter-element=NvBlockNeed_FactoryMode_DefaultValue
            role=defaultValue, used-parameter-element=NvBlockNeed_FactoryMode_DefaultValue
            role=defaultValue, used-parameter-element=NvBlockNeed_FactoryMode_DefaultValue
            role=defaultValue, used-parameter-element=NvBlockNeed_FactoryMode_DefaultValue
            role=defaultValue, used-parameter-element=NvBlockNeed_FactoryMode_DefaultValue
            role=defaultValue, used-parameter-element=NvBlockNeed_FactoryMode_DefaultValue
            role=defaultValue, used-parameter-element=NvBlockNeed_FactoryMode_DefaultValue
            role=defaultValue, used-parameter-element=NvBlockNeed_FactoryMode_DefaultValue
            role=defaultValue, used-parameter-element=NvBlockNeed_FactoryMode_DefaultValue
            role=defaultValue, used-parameter-element=NvBlockNeed_FactoryMode_DefaultValue
            role=defaultValue, used-parameter-element=NvBlockNeed_FactoryMode_DefaultValue
            role=defaultValue, used-parameter-element=NvBlockNeed_FactoryMode_DefaultValue
            role=defaultValue, used-parameter-element=NvBlockNeed_FactoryMode_DefaultValue
            role=defaultValue, used-parameter-element=NvBlockNeed_FactoryMode_DefaultValue
            role=defaultValue, used-parameter-element=NvBlockNeed_FactoryMode_DefaultValue
            role=defaultValue, used-parameter-element=NvBlockNeed_FactoryMode_DefaultValue
            role=defaultValue, used-parameter-element=NvBlockNeed_FactoryMode_DefaultValue
            role=defaultValue, used-parameter-element=NvBlockNeed_FactoryMode_DefaultValue
            role=defaultValue, used-parameter-element=NvBlockNeed_FactoryMode_DefaultValue
            role=defaultValue, used-parameter-element=NvBlockNeed_FactoryMode_DefaultValue
            role=defaultValue, used-parameter-element=NvBlockNeed_FactoryMode_DefaultValue
          assigned-ports:
            port-prototype=NvMNotifyJobFinished_NvBlockNeed_FactoryMode, role=NvMNotifyJobFinished
            port-prototype=NvMService_AC2_SRBS_NvBlockNeed_FactoryMode, role=NvMService_AC2_SRBS
          service-needs:
            nv block needs NvBlockNeed_FactoryMode: n-data-sets=0, ram-block-status-control=API, reliability=NO-PROTECTION, restore-at-start=true, store-at-shutdown=true
        NvBlockNeed_ECUlevelNetworkConfigurationData
          assigned-datas:
            role=ramBlock, used-data-element=NvBlockNeed_ECUlevelNetworkConfigurationData_MirrorBlock
            role=defaultValue, used-parameter-element=NvBlockNeed_ECUlevelNetworkConfigurationData_DefaultValue
            role=defaultValue, used-parameter-element=NvBlockNeed_ECUlevelNetworkConfigurationData_DefaultValue
            role=defaultValue, used-parameter-element=NvBlockNeed_ECUlevelNetworkConfigurationData_DefaultValue
            role=defaultValue, used-parameter-element=NvBlockNeed_ECUlevelNetworkConfigurationData_DefaultValue
            role=defaultValue, used-parameter-element=NvBlockNeed_ECUlevelNetworkConfigurationData_DefaultValue
            role=defaultValue, used-parameter-element=NvBlockNeed_ECUlevelNetworkConfigurationData_DefaultValue
            role=defaultValue, used-parameter-element=NvBlockNeed_ECUlevelNetworkConfigurationData_DefaultValue
            role=defaultValue, used-parameter-element=NvBlockNeed_ECUlevelNetworkConfigurationData_DefaultValue
            role=defaultValue, used-parameter-element=NvBlockNeed_ECUlevelNetworkConfigurationData_DefaultValue
            role=defaultValue, used-parameter-element=NvBlockNeed_ECUlevelNetworkConfigurationData_DefaultValue
            role=defaultValue, used-parameter-element=NvBlockNeed_ECUlevelNetworkConfigurationData_DefaultValue
            role=defaultValue, used-parameter-element=NvBlockNeed_ECUlevelNetworkConfigurationData_DefaultValue
            role=defaultValue, used-parameter-element=NvBlockNeed_ECUlevelNetworkConfigurationData_DefaultValue
            role=defaultValue, used-parameter-element=NvBlockNeed_ECUlevelNetworkConfigurationData_DefaultValue
            role=defaultValue, used-parameter-element=NvBlockNeed_ECUlevelNetworkConfigurationData_DefaultValue
            role=defaultValue, used-parameter-element=NvBlockNeed_ECUlevelNetworkConfigurationData_DefaultValue
            role=defaultValue, used-parameter-element=NvBlockNeed_ECUlevelNetworkConfigurationData_DefaultValue
            role=defaultValue, used-parameter-element=NvBlockNeed_ECUlevelNetworkConfigurationData_DefaultValue
            role=defaultValue, used-parameter-element=NvBlockNeed_ECUlevelNetworkConfigurationData_DefaultValue
            role=defaultValue, used-parameter-element=NvBlockNeed_ECUlevelNetworkConfigurationData_DefaultValue
            role=defaultValue, used-parameter-element=NvBlockNeed_ECUlevelNetworkConfigurationData_DefaultValue
            role=defaultValue, used-parameter-element=NvBlockNeed_ECUlevelNetworkConfigurationData_DefaultValue
            role=defaultValue, used-parameter-element=NvBlockNeed_ECUlevelNetworkConfigurationData_DefaultValue
            role=defaultValue, used-parameter-element=NvBlockNeed_ECUlevelNetworkConfigurationData_DefaultValue
            role=defaultValue, used-parameter-element=NvBlockNeed_ECUlevelNetworkConfigurationData_DefaultValue
            role=defaultValue, used-parameter-element=NvBlockNeed_ECUlevelNetworkConfigurationData_DefaultValue
            role=defaultValue, used-parameter-element=NvBlockNeed_ECUlevelNetworkConfigurationData_DefaultValue
            role=defaultValue, used-parameter-element=NvBlockNeed_ECUlevelNetworkConfigurationData_DefaultValue
            role=defaultValue, used-parameter-element=NvBlockNeed_ECUlevelNetworkConfigurationData_DefaultValue
            role=defaultValue, used-parameter-element=NvBlockNeed_ECUlevelNetworkConfigurationData_DefaultValue
            role=defaultValue, used-parameter-element=NvBlockNeed_ECUlevelNetworkConfigurationData_DefaultValue
            role=defaultValue, used-parameter-element=NvBlockNeed_ECUlevelNetworkConfigurationData_DefaultValue
            role=defaultValue, used-parameter-element=NvBlockNeed_ECUlevelNetworkConfigurationData_DefaultValue
            role=defaultValue, used-parameter-element=NvBlockNeed_ECUlevelNetworkConfigurationData_DefaultValue
            role=defaultValue, used-parameter-element=NvBlockNeed_ECUlevelNetworkConfigurationData_DefaultValue
            role=defaultValue, used-parameter-element=NvBlockNeed_ECUlevelNetworkConfigurationData_DefaultValue
            role=defaultValue, used-parameter-element=NvBlockNeed_ECUlevelNetworkConfigurationData_DefaultValue
            role=defaultValue, used-parameter-element=NvBlockNeed_ECUlevelNetworkConfigurationData_DefaultValue
            role=defaultValue, used-parameter-element=NvBlockNeed_ECUlevelNetworkConfigurationData_DefaultValue
            role=defaultValue, used-parameter-element=NvBlockNeed_ECUlevelNetworkConfigurationData_DefaultValue
            role=defaultValue, used-parameter-element=NvBlockNeed_ECUlevelNetworkConfigurationData_DefaultValue
            role=defaultValue, used-parameter-element=NvBlockNeed_ECUlevelNetworkConfigurationData_DefaultValue
            role=defaultValue, used-parameter-element=NvBlockNeed_ECUlevelNetworkConfigurationData_DefaultValue
            role=defaultValue, used-parameter-element=NvBlockNeed_ECUlevelNetworkConfigurationData_DefaultValue
            role=defaultValue, used-parameter-element=NvBlockNeed_ECUlevelNetworkConfigurationData_DefaultValue
            role=defaultValue, used-parameter-element=NvBlockNeed_ECUlevelNetworkConfigurationData_DefaultValue
            role=defaultValue, used-parameter-element=NvBlockNeed_ECUlevelNetworkConfigurationData_DefaultValue
            role=defaultValue, used-parameter-element=NvBlockNeed_ECUlevelNetworkConfigurationData_DefaultValue
            role=defaultValue, used-parameter-element=NvBlockNeed_ECUlevelNetworkConfigurationData_DefaultValue
            role=defaultValue, used-parameter-element=NvBlockNeed_ECUlevelNetworkConfigurationData_DefaultValue
            role=defaultValue, used-parameter-element=NvBlockNeed_ECUlevelNetworkConfigurationData_DefaultValue
            role=defaultValue, used-parameter-element=NvBlockNeed_ECUlevelNetworkConfigurationData_DefaultValue
            role=defaultValue, used-parameter-element=NvBlockNeed_ECUlevelNetworkConfigurationData_DefaultValue
            role=defaultValue, used-parameter-element=NvBlockNeed_ECUlevelNetworkConfigurationData_DefaultValue
            role=defaultValue, used-parameter-element=NvBlockNeed_ECUlevelNetworkConfigurationData_DefaultValue
            role=defaultValue, used-parameter-element=NvBlockNeed_ECUlevelNetworkConfigurationData_DefaultValue
            role=defaultValue, used-parameter-element=NvBlockNeed_ECUlevelNetworkConfigurationData_DefaultValue
            role=defaultValue, used-parameter-element=NvBlockNeed_ECUlevelNetworkConfigurationData_DefaultValue
            role=defaultValue, used-parameter-element=NvBlockNeed_ECUlevelNetworkConfigurationData_DefaultValue
            role=defaultValue, used-parameter-element=NvBlockNeed_ECUlevelNetworkConfigurationData_DefaultValue
            role=defaultValue, used-parameter-element=NvBlockNeed_ECUlevelNetworkConfigurationData_DefaultValue
            role=defaultValue, used-parameter-element=NvBlockNeed_ECUlevelNetworkConfigurationData_DefaultValue
            role=defaultValue, used-parameter-element=NvBlockNeed_ECUlevelNetworkConfigurationData_DefaultValue
            role=defaultValue, used-parameter-element=NvBlockNeed_ECUlevelNetworkConfigurationData_DefaultValue
          assigned-ports:
            port-prototype=NvMNotifyJobFinished_NvBlockNeed_ECUlevelNetworkConfigurationData, role=NvMNotifyJobFinished
            port-prototype=NvMService_AC2_SRBS_NvBlockNeed_ECUlevelNetworkConfigurationData, role=NvMService_AC2_SRBS
          service-needs:
            nv block needs NvBlockNeed_ECUlevelNetworkConfigurationData: n-data-sets=0, ram-block-status-control=API, reliability=NO-PROTECTION, restore-at-start=true, store-at-shutdown=true
        DiagEventNeed
          service-needs:
            diagnostic event needs DiagEventNeed
        NvBlockNeed_ClusterInternalConfiguration
          assigned-datas:
            role=ramBlock, used-data-element=NvBlockNeed_ClusterInternalConfiguration_MirrorBlock
            role=defaultValue, used-parameter-element=NvBlockNeed_ClusterInternalConfiguration_DefaultValue
            role=defaultValue, used-parameter-element=NvBlockNeed_ClusterInternalConfiguration_DefaultValue
            role=defaultValue, used-parameter-element=NvBlockNeed_ClusterInternalConfiguration_DefaultValue
            role=defaultValue, used-parameter-element=NvBlockNeed_ClusterInternalConfiguration_DefaultValue
          assigned-ports:
            port-prototype=NvMNotifyJobFinished_NvBlockNeed_ClusterInternalConfiguration, role=NvMNotifyJobFinished
            port-prototype=NvMService_AC2_SRBS_NvBlockNeed_ClusterInternalConfiguration, role=NvMService_AC2_SRBS
          service-needs:
            nv block needs NvBlockNeed: n-data-sets=0, ram-block-status-control=API, reliability=NO-PROTECTION, restore-at-start=true
        NvBlockNeed_SecOcSwitch
          assigned-datas:
            role=ramBlock, used-data-element=NvBlockNeed_SecOcSwitch_MirrorBlock
            role=defaultValue, used-parameter-element=NvBlockNeed_SecOcSwitch_DefaultValue
            role=defaultValue, used-parameter-element=NvBlockNeed_SecOcSwitch_DefaultValue
            role=defaultValue, used-parameter-element=NvBlockNeed_SecOcSwitch_DefaultValue
            role=defaultValue, used-parameter-element=NvBlockNeed_SecOcSwitch_DefaultValue
          assigned-ports:
            port-prototype=NvMNotifyJobFinished_NvBlockNeed_SecOcSwitch, role=NvMNotifyJobFinished
            port-prototype=NvMService_AC2_SRBS_NvBlockNeed_SecOcSwitch, role=NvMService_AC2_SRBS
          service-needs:
            nv block needs NvBlockNeed_SecOcSwitch: n-data-sets=0, ram-block-status-control=API, reliability=NO-PROTECTION, restore-at-start=true, store-at-shutdown=false
        NvBlockNeed_E2ESwitch
          assigned-datas:
            role=ramBlock, used-data-element=NvBlockNeed_E2ESwitch_MirrorBlock
            role=defaultValue, used-parameter-element=NvBlockNeed_E2ESwitch_DefaultValue
            role=defaultValue, used-parameter-element=NvBlockNeed_E2ESwitch_DefaultValue
            role=defaultValue, used-parameter-element=NvBlockNeed_E2ESwitch_DefaultValue
            role=defaultValue, used-parameter-element=NvBlockNeed_E2ESwitch_DefaultValue
          assigned-ports:
            port-prototype=NvMNotifyJobFinished_NvBlockNeed_E2ESwitch, role=NvMNotifyJobFinished
            port-prototype=NvMService_AC2_SRBS_NvBlockNeed_E2ESwitch, role=NvMService_AC2_SRBS
          service-needs:
            nv block needs NvBlockNeed_E2ESwitch: n-data-sets=0, ram-block-status-control=API, reliability=NO-PROTECTION, restore-at-start=true, store-at-shutdown=false
        NvBlockNeed_VehicleSoftwareVersion
          assigned-datas:
            role=ramBlock, used-data-element=NvBlockNeed_VehicleSoftwareVersion_MirrorBlock
            role=defaultValue, used-parameter-element=NvBlockNeed_VehicleSoftwareVersion_DefaultValue
          assigned-ports:
            port-prototype=NvMService_AC2_SRBS_NvBlockNeed_VehicleSoftwareVersion, role=NvMService_AC2_SRBS
            port-prototype=NvMNotifyJobFinished_NvBlockNeed_VehicleSoftwareVersion, role=NvMNotifyJobFinished
          service-needs:
            nv block needs NvBlockNeed_VehicleSoftwareVersion: n-data-sets=0, ram-block-status-control=API, reliability=NO-PROTECTION, restore-at-start=true, store-at-shutdown=false
        NvBlockNeed_ClusterDisplayHMIAdjustmentOffset
          assigned-datas:
            role=ramBlock, used-data-element=NvBlockNeed_ClusterDisplayHMIAdjustmentOffset_MirrorBlock
            role=defaultValue, used-parameter-element=NvBlockNeed_ClusterDisplayHMIAdjustmentOffset_DefaultValue
          assigned-ports:
            port-prototype=NvMNotifyJobFinished_NvBlockNeed_ClusterDisplayHMIAdjustmentOffset, role=NvMNotifyJobFinished
            port-prototype=NvMService_AC2_SRBS_NvBlockNeed_ClusterDisplayHMIAdjustmentOffset, role=NvMService_AC2_SRBS_Defs
          service-needs:
            nv block needs NvBlockNeed_ClusterDisplayHMIAdjustmentOffset: n-data-sets=0, ram-block-status-control=API, reliability=NO-PROTECTION, restore-at-start=true, store-at-shutdown=true
      shared-parameters:
        12 x parameter data prototype, all with sw-calibration-access=READ-WRITE:
          NvBlockNeed_VIN_DefaultValue: type=A_17Bytes, init-value=17 x 255
          NvBlockNeed_MasterSlaveStatus_DefaultValue: type=A_8Bytes
          NvBlockNeed_SwitchARLTable_DefaultValue: type=A_28Bytes, init-value=28 x 0
          NvBlockNeed_VehicleMode_DefaultValue: type=Dcm_Data20ByteType, init-value=20 x 255
          NvBlockNeed_FactoryMode_DefaultValue: type=A_1Bytes, init-value=[1]
          NvBlockNeed_ECUlevelNetworkConfigurationData_DefaultValue: type=A_200Bytes, init-value=[105, 106, 19, 39, 1, 4, 0, 5, 96, 98, 84, 105, 88, 17, 84, 64, 65, 97, 80, 64, 133, 21, 0, 73, 160, 5, 66, 109, 148, 0, 21, 43, 68, 83, 0, 0, 18, 81, 65, 8, 0, 1, 1, 1, 1, 32, 36, 68, 99, 67, 68, 16, 0, 0, 64, 7, 76, 66, 0, 0, 0, 0, 0, 97, 32, 0, 0, 0, 8, 0, 0, 0, 48, 0, 64, 11, 0, 0, 48, 64, 4, 51, 0, 16, 0, 0, 0, 1, 0, 0, 0, 0, 0, 0, 0, 0, 0, 0, 0, 0, 0, 0, 0, 0, 0, 0, 0, 0, 0, 0, 0, 0, 0, 0, 0, 0, 0, 0, 0, 0, 0, 0, 0, 0, 0, 0, 0, 0, 0, 0, 0, 0, 0, 0, 0, 0, 0, 0, 0, 0, 0, 0, 0, 0, 0, 0, 0, 0, 0, 0, 0, 0, 0, 0, 0, 0, 0, 0, 0, 0, 0, 0, 0, 0, 0, 0, 0, 0, 0, 0, 0, 0, 0, 0, 0, 0, 0, 0, 0, 0, 0, 0, 0, 0, 0, 0, 0, 0, 0, 0, 0, 0, 0, 0, 0, 0, 0, 0, 0, 0]
          NvBlockNeed_HUTInternalConfiguration_DefaultValue: type=Dcm_Data4ByteType
          NvBlockNeed_ClusterInternalConfiguration_DefaultValue: type=A_300Bytes, init-value=[12, 132, 26, 13, 0, 0, 10, 90, 110, 125, 162, 166, 168, 180, 90, 110, 125, 158, 163, 165, 170, 0, 160, 3, 232, 6, 64, 100, 1, 64, 50, 0, 32, 2, 1, 144, 1, 144, 1, 144, 20, 0, 30, 50, 0, 25, 12, 128, 200, 6, 64, 50, 47, 48, 90, 7, 128, 33, 177, 33, 177, 21, 249, 0, 0, 0, 50, 47, 48, 100, 8, 32, 21, 249, 21, 249, 21, 249, 0, 0, 0, 50, 47, 48, 100, 8, 32, 75, 4, 176, 75, 4, 176, 0, 0, 0, 50, 47, 48, 100, 8, 32, 0, 0, 0, 0, 0, 0, 0, 0, 0, 50, 47, 48, 100, 8, 32, 0, 0, 0, 0, 0, 0, 0, 0, 12, 128, 30, 68, 40, 24, 6, 64, 3, 240, 0, 0, 54, 238, 118, 6, 64, 7, 158, 60, 0, 165, 0, 192, 6, 64, 10, 0, 0, 50, 18, 176, 20, 10, 1, 3, 10, 40, 0, 0, 1, 232, 0, 0, 0, 0, 0, 128, 254, 0, 128, 0, 0, 0, 0, 128, 0, 161, 100, 0, 1, 61, 224, 2, 128, 10, 128, 10, 131, 231, 0, 161, 0, 0, 24, 6, 64, 3, 192, 0, 0, 54, 238, 118, 254, 0, 0, 0, 0, 0, 131, 121, 30, 1, 56, 128, 120, 120, 15, 60, 15, 160, 6, 5, 40, 20, 2, 4, 1, 24, 105, 241, 134, 159, 17, 2, 136, 15, 156, 20, 20, 0, 0, 160, 2, 0, 32, 2, 0, 160, 10, 30, 0, 160, 10, 0, 0, 0, 20, 3, 32, 100, 3, 34, 243, 6, 224, 160, 3, 34, 243, 8, 192, 170, 12, 4, 20, 20, 20, 2, 0, 160, 20, 20, 1, 244, 2, 1, 5, 0, 0, 0, 0, 0, 0]
          NvBlockNeed_SecOcSwitch_DefaultValue: type=A_1Bytes, init-value=[1]
          NvBlockNeed_E2ESwitch_DefaultValue: type=A_1Bytes, init-value=[1]
          NvBlockNeed_VehicleSoftwareVersion_DefaultValue: type=A_30Bytes, init-value=[86, 49, 46, 48, 255, 255, 255, 255, 255, 255, 255, 255, 255, 255, 255, 255, 255, 255, 255, 255, 255, 255, 255, 255, 255, 255, 255, 255, 255, 255]
          NvBlockNeed_ClusterDisplayHMIAdjustmentOffset_DefaultValue: type=A_8Bytes, init-value=8 x 0
  swc implementation DidDataProcess_Implementation: behavior=DidDataProcess_InternalBehavior
